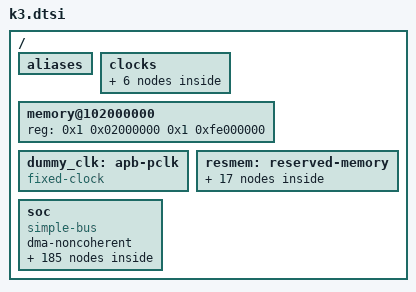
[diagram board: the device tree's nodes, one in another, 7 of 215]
// SPDX-License-Identifier: (GPL-2.0 OR MIT)
/* Copyright (c) 2025 Spacemit, Inc */

/dts-v1/;

/* Inline SoC GPIO helper: expand a linear GPIO to <bank,offset> */
#define K3_GPIO(x) ((x) / 32) ((x) % 32)
#include "k3-cpus.dtsi"
#include "k3-trace.dtsi"
#include <dt-bindings/gpio/gpio.h>
#include <dt-bindings/clock/spacemit,k3-syscon.h>
#include <dt-bindings/interrupt-controller/irq.h>
#include <dt-bindings/pmu/k3_pmu.h>
#include <dt-bindings/dma/k3-dmac.h>
#include <dt-bindings/leds/common.h>

/ {
	#address-cells = <2>;
	#size-cells = <2>;

	aliases {
		serial0 = &uart0;
		serial1 = &uart1;
		serial2 = &uart2;
		serial3 = &uart3;
		serial4 = &uart4;
		serial5 = &uart5;
		serial6 = &uart6;
		serial7 = &uart7;
		serial8 = &uart8;
		serial9 = &uart9;
		serial10 = &uart10;
		serial11 = &r_uart0;
		serial12 = &r_uart1;
		serial13 = &r_uart2;
		serial14 = &r_uart3;
		serial15 = &r_uart4;
		serial16 = &r_uart5;
		mmc0 = &sdcard;
		mmc1 = &sdio;
		mmc2 = &emmc;
		ethernet0 = &eth0;
		ethernet1 = &eth1;
		ethernet2 = &eth2;
		ethernet3 = &eth3;
		i2c0 = &i2c0;
		i2c1 = &i2c1;
		i2c2 = &i2c2;
		i2c3 = &i2c3;
		i2c4 = &i2c4;
		i2c5 = &i2c5;
		i2c6 = &i2c6;
		i2c8 = &i2c8;
		spi0 = &spi0;
		spi1 = &spi1;
		spi2 = &spi2;
		spi3 = &spi3;
	};

	clocks {
		vctcxo_1m: clock-1m {
			compatible = "fixed-clock";
			clock-frequency = <1000000>;
			clock-output-names = "vctcxo_1m";
			#clock-cells = <0>;
		};

		vctcxo_24m: clock-24m {
			compatible = "fixed-clock";
			clock-frequency = <24000000>;
			clock-output-names = "vctcxo_24m";
			#clock-cells = <0>;
		};

		vctcxo_3m: clock-3m {
			compatible = "fixed-clock";
			clock-frequency = <3000000>;
			clock-output-names = "vctcxo_3m";
			#clock-cells = <0>;
		};

		osc_32k: clock-32k {
			compatible = "fixed-clock";
			clock-frequency = <32768>;
			clock-output-names = "osc_32k";
			#clock-cells = <0>;
		};

		reserved_clk: clock-reserved {
			compatible = "fixed-clock";
			clock-frequency = <0>;
			clock-output-names = "reserved_clk";
			#clock-cells = <0>;
		};

		external_clk: clock-external {
			compatible = "fixed-clock";
			clock-frequency = <0>;
			clock-output-names = "external_clk";
			#clock-cells = <0>;
		};
	};

	memory@102000000 {
		device_type = "memory";
		reg = <0x1 0x02000000 0x1 0xfe000000>;
	};

	dummy_clk: apb-pclk {
		compatible = "fixed-clock";
		#clock-cells = <0x0>;
		clock-output-names = "clk14mhz";
		clock-frequency = <14000000>;
	};

	resmem: reserved-memory {
		#address-cells = <2>;
		#size-cells = <2>;
		ranges;

		/* used for rcpu0 code & data & bss space */
		rcpu0_pwr: rcpu0_pwr@100200000 {
			reg = <0x1 0x200000 0x0 0x300000>;
			no-map;
		};

		/* rcpu0's heap */
		rcpu0_heap: rcpu0_heap@100500000 {
			reg = <0x1 0x500000 0x0 0x200000>;
			no-map;
		};

		/* vring0 */
		rcpu0_vdev0vring0: vdev0vring0@c0876000 {
			reg = <0x0 0xc0876000 0x0 0x3000>;
			no-map;
		};

		/* vring1 */
		rcpu0_vdev0vring1: vdev0vring1@c0879000 {
			reg = <0x0 0xc0879000 0x0 0x3000>;
			no-map;
		};

		/* vring2 */
		rcpu0_vdev0vring2: vdev0vring2@c087c000 {
			reg = <0x0 0xc087c000 0x0 0x1000>;
			no-map;
		};

		/* the rcpu0's share memory buffer */
		rcpu0_vdev0buffer: vdev0buffer@100700000 {
			compatible = "shared-dma-pool";
			reg = <0x1 0x700000 0x0 0xfc000>;
			no-map;
		};

		/* the rcpu0's resource table */
		rcpu0_rsc_table: rcpu0_rsc_table@1007fc000 {
			reg = <0x1 0x7fc000 0x0 0x4000>;
			no-map;
		};

		/* rpmi */
		rpmi0: rpmi0@100800000 {
			reg = <0x1 0x00800000 0x0 0x4000>;
			no-map;
		};

		/*****************rcpu1**********************/
		/* used for rcp1 code & data & bss space */
		rcpu1_runtime: rcpu1_runtime@100804000 {
			reg = <0x1 0x804000 0x0 0x300000>;
			no-map;
		};

		/* rcpu1's heap */
		rcpu1_heap: rcpu1_heap@100B04000 {
			reg = <0x1 0xb04000 0x0 0x200000>;
			no-map;
		};

		/* vring0 */
		rcpu1_vdev0vring0: vdev0vring0@c086c000 {
			reg = <0x0 0xc086c000 0x0 0x3000>;
			no-map;
		};

		/* vring1 */
		rcpu1_vdev0vring1: vdev0vring1@c086f000 {
			reg = <0x0 0xc086f000 0x0 0x3000>;
			no-map;
		};

		/* the rcpu1's share memory buffer */
		rcpu1_vdev0buffer: vdev0buffer@100d04000 {
			compatible = "shared-dma-pool";
			reg = <0x1 0xd04000 0x0 0xfc000>;
			no-map;
		};

		/* the rcpu1's resource table */
		rcpu1_rsc_table: rcpu1_rsc_table@100e00000 {
			reg = <0x1 0xe00000 0x0 0x4000>;
			no-map;
		};

		/* reserve 3M for rcpu's dtb space */
		rcpu_dtb_table: rcpu_dtb_table@100e04000 {
			reg = <0x1 0xe04000 0x0 0x300000>;
			no-map;
		};

		/* reserved 5M for dpu, including mmu table and cmdlist */
		dpu_resv0: dpu_reserved@101b00000 {
			compatible = "shared-dma-pool";
			reg = <0x1 0x01b00000 0x0 0x00280000>;
			no-map;
		};

		dpu_resv1: dpu_reserved1@101d80000 {
			compatible = "shared-dma-pool";
			reg = <0x1 0x01d80000 0x0 0x00280000>;
			no-map;
		};
	};

	soc: soc {
		#address-cells = <2>;
		#size-cells = <2>;
		compatible = "simple-bus";
		dma-noncoherent;
		ranges;

		clint0: clint@e081c000 {
			compatible = "riscv,clint0";
			interrupts-extended = <
				&cpu0_intc  3 &cpu0_intc  7
				&cpu1_intc  3 &cpu1_intc  7
				&cpu2_intc  3 &cpu2_intc  7
				&cpu3_intc  3 &cpu3_intc  7
				&cpu4_intc  3 &cpu4_intc  7
				&cpu5_intc  3 &cpu5_intc  7
				&cpu6_intc  3 &cpu6_intc  7
				&cpu7_intc  3 &cpu7_intc  7
				&cpu8_intc  3 &cpu8_intc  7
				&cpu9_intc  3 &cpu9_intc  7
				&cpu10_intc  3 &cpu10_intc  7
				&cpu11_intc  3 &cpu11_intc  7
				&cpu12_intc  3 &cpu12_intc  7
				&cpu13_intc  3 &cpu13_intc  7
				&cpu14_intc  3 &cpu14_intc  7
				&cpu15_intc  3 &cpu15_intc  7
			>;
			reg = <0x0 0xe081c000 0x0 0x0004000>;
		};

		simsic: interrupt-controller@e0400000 {
			compatible = "riscv,imsics";
			interrupts-extended = <
				&cpu0_intc 9 &cpu1_intc 9
				&cpu2_intc 9 &cpu3_intc 9
				&cpu4_intc 9 &cpu5_intc 9
				&cpu6_intc 9 &cpu7_intc 9
				&cpu8_intc 9 &cpu9_intc 9
				&cpu10_intc 9 &cpu11_intc 9
				&cpu12_intc 9 &cpu13_intc 9
				&cpu14_intc 9 &cpu15_intc 9>;

			reg = <0x0 0xe0400000 0x0 0x400000>;
			interrupt-controller;
			#interrupt-cells = <0>;
			#msi-cells = <0>;
			msi-controller;
			/* Number of interrupt identities: 511 */
			riscv,num-ids = <511>;
			/* Number of guest interrupt identities: 511 */
			riscv,num-guest-ids = <511>;
			/* Number of HART index bits: 4 (2^4 = 16 harts) */
			riscv,hart-index-bits = <4>;
			/*
			 * Number of guest index bits: 6
			 *    2^6 = 64 interrupt files
			 *        = 1 s-level interrupt file + 63 vs-level interrupt files
			 *
			 * But on K3,
			 *   X100: only 7 of the 63 vs-level interrupt files are valid.
			 *   A100: no valid vs-level interrupt files.
			 */
			riscv,guest-index-bits = <6>;
			status = "okay";
		};

		saplic: interrupt-controller@e0804000 {
			compatible = "riscv,aplic";
			/* aplic config */
			reg = <0x0 0xe0804000 0x0 0x4000>;
			msi-parent = <&simsic>;
			#interrupt-cells = <2>;
			interrupt-controller;
			/* the number of wired interrupt sources:512 */
			riscv,num-sources = <512>;
			status = "okay";
		};

		syscon_mpmu: system-controller@d4050000 {
			compatible = "spacemit,k3-syscon-mpmu";
			reg = <0x0 0xd4050000 0x0 0x10000>;
			clocks = <&osc_32k>, <&vctcxo_1m>, <&vctcxo_3m>,
				 <&vctcxo_24m>, <&reserved_clk>, <&external_clk>;
			clock-names = "osc_32k", "vctcxo_1m", "vctcxo_3m", "vctcxo_24m",
				      "reserved_clk", "external_clk";
			#clock-cells = <1>;
			#reset-cells = <1>;
		};

		pll: clock-controller@d4090000 {
			compatible = "spacemit,k3-pll";
			reg = <0x0 0xd4090000 0x0 0x10000>;
			clocks = <&vctcxo_24m>;
			spacemit,mpmu = <&syscon_mpmu>;
			#clock-cells = <1>;
		};

		syscon_apmu: system-controller@d4282800 {
			compatible = "spacemit,k3-syscon-apmu";
			reg = <0x0 0xd4282800 0x0 0x400>;
			clocks = <&osc_32k>, <&vctcxo_1m>, <&vctcxo_3m>, <&vctcxo_24m>,
				 <&reserved_clk>, <&external_clk>;
			clock-names = "osc_32k", "vctcxo_1m", "vctcxo_3m", "vctcxo_24m",
				      "reserved_clk", "external_clk";
			#clock-cells = <1>;
			#power-domain-cells = <1>;
			#reset-cells = <1>;
		};

		syscon_apbc: system-controller@d4015000 {
			compatible = "spacemit,k3-syscon-apbc";
			reg = <0x0 0xd4015000 0x0 0x1000>;
			clocks = <&osc_32k>, <&vctcxo_1m>, <&vctcxo_3m>, <&vctcxo_24m>,
				 <&reserved_clk>, <&external_clk>;
			clock-names = "osc_32k", "vctcxo_1m", "vctcxo_3m", "vctcxo_24m",
				      "reserved_clk", "external_clk";
			#clock-cells = <1>;
			#reset-cells = <1>;
		};

		syscon_apbc2: system-controller@f0610000 {
			compatible = "spacemit,k3-syscon-apbc2";
			reg = <0x0 0xf0610000 0x0 0x2000>;
			clocks = <&osc_32k>, <&vctcxo_1m>, <&vctcxo_3m>, <&vctcxo_24m>,
				 <&reserved_clk>, <&external_clk>;
			clock-names = "osc_32k", "vctcxo_1m", "vctcxo_3m", "vctcxo_24m",
				      "reserved_clk", "external_clk";
			#clock-cells = <1>;
			#reset-cells = <1>;
		};

		syscon_dciu: system-controller@d8440000 {
			compatible = "spacemit,k3-syscon-dciu";
			reg = <0x0 0xd8440000 0x0 0xc000>;
			#clock-cells = <1>;
			#reset-cells = <1>;
		};

		syscon_rcpu_sysctrl: system-controller@c0880000 {
			compatible = "spacemit,k3-syscon-rcpu-sysctrl";
			reg = <0x0 0xc0880000 0x0 0x1000>;
			clocks = <&vctcxo_24m>, <&external_clk>;
			clock-names = "vctcxo_24m", "external_clk";
			#clock-cells = <1>;
			#reset-cells = <1>;
		};

		syscon_rcpu_uartctrl: system-controller@c0881f00 {
			compatible = "spacemit,k3-syscon-rcpu-uartctrl";
			reg = <0x0 0xc0881f00 0x0 0x100>;
			#clock-cells = <1>;
			#reset-cells = <1>;
		};

		syscon_rcpu_i2sctrl: system-controller@c0882000 {
			compatible = "spacemit,k3-syscon-rcpu-i2sctrl";
			reg = <0x0 0xc0882000 0x0 0x1000>;
			#clock-cells = <1>;
			#reset-cells = <1>;
		};

		syscon_rcpu_spictrl: system-controller@c0885f00 {
			compatible = "spacemit,k3-syscon-rcpu-spictrl";
			reg = <0x0 0xc0885f00 0x0 0x100>;
			#clock-cells = <1>;
			#reset-cells = <1>;
		};

		syscon_rcpu_i2cctrl: system-controller@c0886f00 {
			compatible = "spacemit,k3-syscon-rcpu-i2cctrl";
			reg = <0x0 0xc0886f00 0x0 0x100>;
			#clock-cells = <1>;
			#reset-cells = <1>;
		};

		syscon_rpmu: system-controller@c088c000 {
			compatible = "spacemit,k3-syscon-rpmu";
			reg = <0x0 0xc088c000 0x0 0x800>;
			#clock-cells = <1>;
			#reset-cells = <1>;
		};

		syscon_rcpu_pwmctrl: system-controller@c088d000 {
			compatible = "spacemit,k3-syscon-rcpu-pwmctrl";
			reg = <0x0 0xc088d000 0x0 0x100>;
			#clock-cells = <1>;
			#reset-cells = <1>;
		};

		syscon_gpio: syscon-gpio{
			compatible = "syscon";
			reg = <0x0 0xd4019000 0x0 0x800>;
		};

		syscon_gpio_edge: syscon-gpio-edge{
			compatible = "syscon";
			reg = <0x0 0xd4019800 0x0 0x10>;
		};

		gpio: gpio@d4019000 {
			compatible = "spacemit,k3-gpio";
			reg = <0x0 0xd4019000 0x0 0x100>;
			clocks = <&syscon_apbc CLK_APBC_GPIO>,
				 <&syscon_apbc CLK_APBC_GPIO_BUS>;
			clock-names = "core", "bus";
			gpio-controller;
			#gpio-cells = <3>;
			interrupts = <58 IRQ_TYPE_LEVEL_HIGH>;
			interrupt-parent = <&saplic>;
			interrupt-controller;
			#interrupt-cells = <3>;
			syscon-gpio-regs = <&syscon_gpio>;
			syscon-gpio-edge = <&syscon_gpio_edge>;
			gpio-ranges = <&pinctrl 0 0 0 32>,
				      <&pinctrl 1 0 32 32>,
				      <&pinctrl 2 0 64 32>,
				      <&pinctrl 3 0 96 32>;
		};

		pinctrl: pinctrl@d401e000 {
			compatible = "spacemit,k3-pinctrl";
			reg = <0x0 0xd401e000 0x0 0x400>,
			      <0x0 0xd401e800 0x0 0x34>;
			clocks = <&syscon_apbc CLK_APBC_AIB>,
                                <&syscon_apbc CLK_APBC_AIB_BUS>;
			clock-names = "func", "bus";
			interrupt-controller;
			#interrupt-cells = <2>;
			interrupts = <60 IRQ_TYPE_LEVEL_HIGH>;
			interrupt-parent = <&saplic>;
			spacemit,gpio-edge = <&syscon_gpio_edge>;
			spacemit,apbc = <&syscon_apbc 0x50>;
			spacemit,apmu = <&syscon_apmu>;
		};

		pdma: pdma@d4000000 {
			compatible = "spacemit,k1-pdma";
			reg = <0x0 0xd4000000 0x0 0x4000>;
			interrupt-parent = <&saplic>;
			interrupts = <72 IRQ_TYPE_LEVEL_HIGH>;
			clocks = <&syscon_apmu CLK_APMU_DMA>;
			resets = <&syscon_apmu RESET_APMU_DMA>;
			#dma-cells= <1>;
			#dma-channels = <16>;
			max-burst-size = <64>;
			status = "okay";
		};

		pdma1: pdma@f0600000 {
			compatible = "spacemit,k1-pdma";
			reg = <0x0 0xf0600000 0x0 0x4000>;
			interrupt-parent = <&saplic>;
			interrupts = <150 IRQ_TYPE_LEVEL_HIGH>;
			#dma-cells= <1>;
			#dma-channels = <16>;
			max-burst-size = <64>;
			status = "disabled";
		};

		udma: udma {
			compatible = "spacemit,udma";
			status = "okay";
		};

		uart0: serial@d4017000 {
			compatible = "spacemit,k1-uart",
				     "intel,xscale-uart";
			reg = <0x0 0xd4017000 0x0 0x100>;
			clocks = <&syscon_apbc CLK_APBC_UART0>,
				 <&syscon_apbc CLK_APBC_UART0_BUS>,
				 <&syscon_mpmu CLK_MPMU_SLOW_UART>;
			clock-names = "core", "bus", "gate";
			resets = <&syscon_apbc RESET_APBC_UART0>;
			reg-shift = <2>;
			reg-io-width = <4>;
			fifo-size = <256>;
			tx-threshold = <32>;
			interrupt-parent = <&saplic>;
			interrupts = <42 IRQ_TYPE_LEVEL_HIGH>;
			status = "okay";
		};

		uart1: serial@f0612000 {
			compatible = "spacemit,k1-uart",
				     "intel,xscale-uart";
			reg = <0x0 0xf0612000 0x0 0x100>;
			clocks = <&syscon_apbc2 CLK_APBC2_SEC_UART1>,
				 <&syscon_apbc2 CLK_APBC2_SEC_UART1_BUS>,
				 <&syscon_mpmu CLK_MPMU_SLOW_UART>;
			clock-names = "core", "bus", "gate";
			resets = <&syscon_apbc2 RESET_APBC2_SEC_UART1>;
			reg-shift = <2>;
			reg-io-width = <4>;
			fifo-size = <256>;
			tx-threshold = <32>;
			interrupt-parent = <&saplic>;
			interrupts = <43 IRQ_TYPE_LEVEL_HIGH>;
			status = "disabled";
		};

		uart2: serial@d4017100 {
			compatible = "spacemit,k1-uart",
				     "intel,xscale-uart";
			reg = <0x0 0xd4017100 0x0 0x100>;
			clocks = <&syscon_apbc CLK_APBC_UART2>,
				 <&syscon_apbc CLK_APBC_UART2_BUS>,
				 <&syscon_mpmu CLK_MPMU_SLOW_UART>;
			clock-names = "core", "bus", "gate";
			resets = <&syscon_apbc RESET_APBC_UART2>;
			reg-shift = <2>;
			reg-io-width = <4>;
			fifo-size = <256>;
			tx-threshold = <32>;
			interrupt-parent = <&saplic>;
			interrupts = <44 IRQ_TYPE_LEVEL_HIGH>;
			status = "disabled";
		};

		uart3: serial@d4017200 {
			compatible = "spacemit,k1-uart",
				     "intel,xscale-uart";
			reg = <0x0 0xd4017200 0x0 0x100>;
			clocks = <&syscon_apbc CLK_APBC_UART3>,
				 <&syscon_apbc CLK_APBC_UART3_BUS>,
				 <&syscon_mpmu CLK_MPMU_SLOW_UART>;
			clock-names = "core", "bus", "gate";
			resets = <&syscon_apbc RESET_APBC_UART3>;
			reg-shift = <2>;
			reg-io-width = <4>;
			fifo-size = <256>;
			tx-threshold = <32>;
			interrupt-parent = <&saplic>;
			interrupts = <45 IRQ_TYPE_LEVEL_HIGH>;
			status = "disabled";
		};

		uart4: serial@d4017300 {
			compatible = "spacemit,k1-uart",
				     "intel,xscale-uart";
			reg = <0x0 0xd4017300 0x0 0x100>;
			clocks = <&syscon_apbc CLK_APBC_UART4>,
				 <&syscon_apbc CLK_APBC_UART4_BUS>,
				 <&syscon_mpmu CLK_MPMU_SLOW_UART>;
			clock-names = "core", "bus", "gate";
			resets = <&syscon_apbc RESET_APBC_UART4>;
			reg-shift = <2>;
			reg-io-width = <4>;
			fifo-size = <256>;
			tx-threshold = <32>;
			interrupt-parent = <&saplic>;
			interrupts = <46 IRQ_TYPE_LEVEL_HIGH>;
			status = "disabled";
		};

		uart5: serial@d4017400 {
			compatible = "spacemit,k1-uart",
				     "intel,xscale-uart";
			reg = <0x0 0xd4017400 0x0 0x100>;
			clocks = <&syscon_apbc CLK_APBC_UART5>,
				 <&syscon_apbc CLK_APBC_UART5_BUS>,
				 <&syscon_mpmu CLK_MPMU_SLOW_UART>;
			clock-names = "core", "bus", "gate";
			resets = <&syscon_apbc RESET_APBC_UART5>;
			reg-shift = <2>;
			reg-io-width = <4>;
			fifo-size = <256>;
			tx-threshold = <32>;
			interrupt-parent = <&saplic>;
			interrupts = <47 IRQ_TYPE_LEVEL_HIGH>;
			status = "disabled";
		};

		uart6: serial@d4017500 {
			compatible = "spacemit,k1-uart",
				     "intel,xscale-uart";
			reg = <0x0 0xd4017500 0x0 0x100>;
			clocks = <&syscon_apbc CLK_APBC_UART6>,
				 <&syscon_apbc CLK_APBC_UART6_BUS>,
				 <&syscon_mpmu CLK_MPMU_SLOW_UART>;
			clock-names = "core", "bus", "gate";
			resets = <&syscon_apbc RESET_APBC_UART6>;
			reg-shift = <2>;
			reg-io-width = <4>;
			fifo-size = <256>;
			tx-threshold = <32>;
			interrupt-parent = <&saplic>;
			interrupts = <48 IRQ_TYPE_LEVEL_HIGH>;
			status = "disabled";
		};

		uart7: serial@d4017600 {
			compatible = "spacemit,k1-uart",
				     "intel,xscale-uart";
			reg = <0x0 0xd4017600 0x0 0x100>;
			clocks = <&syscon_apbc CLK_APBC_UART7>,
				 <&syscon_apbc CLK_APBC_UART7_BUS>,
				 <&syscon_mpmu CLK_MPMU_SLOW_UART>;
			clock-names = "core", "bus", "gate";
			resets = <&syscon_apbc RESET_APBC_UART7>;
			reg-shift = <2>;
			reg-io-width = <4>;
			fifo-size = <256>;
			tx-threshold = <32>;
			interrupt-parent = <&saplic>;
			interrupts = <49 IRQ_TYPE_LEVEL_HIGH>;
			status = "disabled";
		};

		uart8: serial@d4017700 {
			compatible = "spacemit,k1-uart",
				     "intel,xscale-uart";
			reg = <0x0 0xd4017700 0x0 0x100>;
			clocks = <&syscon_apbc CLK_APBC_UART8>,
				 <&syscon_apbc CLK_APBC_UART8_BUS>,
				 <&syscon_mpmu CLK_MPMU_SLOW_UART>;
			clock-names = "core", "bus", "gate";
			resets = <&syscon_apbc RESET_APBC_UART8>;
			reg-shift = <2>;
			reg-io-width = <4>;
			fifo-size = <256>;
			tx-threshold = <32>;
			interrupt-parent = <&saplic>;
			interrupts = <50 IRQ_TYPE_LEVEL_HIGH>;
			status = "disabled";
		};

		uart9: serial@d4017800 {
			compatible = "spacemit,k1-uart",
				     "intel,xscale-uart";
			reg = <0x0 0xd4017800 0x0 0x100>;
			clocks = <&syscon_apbc CLK_APBC_UART9>,
				 <&syscon_apbc CLK_APBC_UART9_BUS>,
				 <&syscon_mpmu CLK_MPMU_SLOW_UART>;
			clock-names = "core", "bus", "gate";
			resets = <&syscon_apbc RESET_APBC_UART9>;
			reg-shift = <2>;
			reg-io-width = <4>;
			fifo-size = <256>;
			tx-threshold = <32>;
			interrupt-parent = <&saplic>;
			interrupts = <51 IRQ_TYPE_LEVEL_HIGH>;
			status = "disabled";
		};

		uart10: serial@d401f000 {
			compatible = "spacemit,k1-uart",
				     "intel,xscale-uart";
			reg = <0x0 0xd401f000 0x0 0x100>;
			clocks = <&syscon_apbc CLK_APBC_UART10>,
				 <&syscon_apbc CLK_APBC_UART10_BUS>,
				 <&syscon_mpmu CLK_MPMU_SLOW_UART>;
			clock-names = "core", "bus", "gate";
			resets = <&syscon_apbc RESET_APBC_UART10>;
			reg-shift = <2>;
			reg-io-width = <4>;
			fifo-size = <256>;
			tx-threshold = <32>;
			interrupt-parent = <&saplic>;
			interrupts = <281 IRQ_TYPE_LEVEL_HIGH>;
			status = "disabled";
		};

		i2c0: i2c@d4010800 {
			compatible = "spacemit,k1-i2c";
			reg = <0x0 0xd4010800 0x0 0x38>;
			#address-cells = <1>;
			#size-cells = <0>;
			interrupt-parent = <&saplic>;
			interrupts = <36 IRQ_TYPE_LEVEL_HIGH>;
			clocks = <&syscon_apbc CLK_APBC_TWSI0>,
				 <&syscon_apbc CLK_APBC_TWSI0_BUS>;
			clock-names = "func", "bus";
			clock-frequency = <400000>;
			resets = <&syscon_apbc RESET_APBC_TWSI0>;
			power-domains = <&power K3_PMU_DUMMY_PWR_DOMAIN>;
			status = "disabled";
		};

		i2c1: i2c@d4011000 {
			compatible = "spacemit,k1-i2c";
			reg = <0x0 0xd4011000 0x0 0x38>;
			#address-cells = <1>;
			#size-cells = <0>;
			interrupt-parent = <&saplic>;
			interrupts = <37 IRQ_TYPE_LEVEL_HIGH>;
			clocks = <&syscon_apbc CLK_APBC_TWSI1>,
				 <&syscon_apbc CLK_APBC_TWSI1_BUS>;
			clock-names = "func", "bus";
			clock-frequency = <400000>;
			resets = <&syscon_apbc RESET_APBC_TWSI1>;
			power-domains = <&power K3_PMU_DUMMY_PWR_DOMAIN>;
			status = "disabled";
		};

		i2c2: i2c@d4012000 {
			compatible = "spacemit,k1-i2c";
			reg = <0x0 0xd4012000 0x0 0x38>;
			#address-cells = <1>;
			#size-cells = <0>;
			interrupt-parent = <&saplic>;
			interrupts = <38 IRQ_TYPE_LEVEL_HIGH>;
			clocks = <&syscon_apbc CLK_APBC_TWSI2>,
				 <&syscon_apbc CLK_APBC_TWSI2_BUS>;
			clock-names = "func", "bus";
			clock-frequency = <400000>;
			resets = <&syscon_apbc RESET_APBC_TWSI2>;
			power-domains = <&power K3_PMU_DUMMY_PWR_DOMAIN>;
			status = "disabled";
		};

		i2c3: i2c@f0614000 {
			compatible = "spacemit,k1-i2c";
			reg = <0x0 0xf0614000 0x0 0x38>;
			#address-cells = <1>;
			#size-cells = <0>;
			interrupt-parent = <&saplic>;
			interrupts = <39 IRQ_TYPE_LEVEL_HIGH>;
			clocks = <&syscon_apbc2 CLK_APBC2_SEC_TWSI3>,
				 <&syscon_apbc2 CLK_APBC2_SEC_TWSI3_BUS>;
			clock-names = "func", "bus";
			clock-frequency = <400000>;
			resets = <&syscon_apbc2 RESET_APBC2_SEC_TWSI3>;
			power-domains = <&power K3_PMU_DUMMY_PWR_DOMAIN>;
			status = "disabled";
		};

		i2c4: i2c@d4012800 {
			compatible = "spacemit,k1-i2c";
			reg = <0x0 0xd4012800 0x0 0x38>;
			#address-cells = <1>;
			#size-cells = <0>;
			interrupt-parent = <&saplic>;
			interrupts = <40 IRQ_TYPE_LEVEL_HIGH>;
			clocks = <&syscon_apbc CLK_APBC_TWSI4>,
				 <&syscon_apbc CLK_APBC_TWSI4_BUS>;
			clock-names = "func", "bus";
			clock-frequency = <400000>;
			resets = <&syscon_apbc RESET_APBC_TWSI4>;
			power-domains = <&power K3_PMU_DUMMY_PWR_DOMAIN>;
			status = "disabled";
		};

		i2c5: i2c@d4013800 {
			compatible = "spacemit,k1-i2c";
			reg = <0x0 0xd4013800 0x0 0x38>;
			#address-cells = <1>;
			#size-cells = <0>;
			interrupt-parent = <&saplic>;
			interrupts = <41 IRQ_TYPE_LEVEL_HIGH>;
			clocks = <&syscon_apbc CLK_APBC_TWSI5>,
				 <&syscon_apbc CLK_APBC_TWSI5_BUS>;
			clock-names = "func", "bus";
			clock-frequency = <400000>;
			resets = <&syscon_apbc RESET_APBC_TWSI5>;
			power-domains = <&power K3_PMU_DUMMY_PWR_DOMAIN>;
			status = "disabled";
		};

		i2c6: i2c@d4018800 {
			compatible = "spacemit,k1-i2c";
			reg = <0x0 0xd4018800 0x0 0x38>;
			#address-cells = <1>;
			#size-cells = <0>;
			interrupt-parent = <&saplic>;
			interrupts = <70 IRQ_TYPE_LEVEL_HIGH>;
			clocks = <&syscon_apbc CLK_APBC_TWSI6>,
				 <&syscon_apbc CLK_APBC_TWSI6_BUS>;
			clock-names = "func", "bus";
			clock-frequency = <400000>;
			resets = <&syscon_apbc RESET_APBC_TWSI6>;
			power-domains = <&power K3_PMU_DUMMY_PWR_DOMAIN>;
			status = "disabled";
		};

		i2c8: i2c@d401d800 {
			compatible = "spacemit,k1-i2c";
			reg = <0x0 0xd401d800 0x0 0x38>;
			#address-cells = <1>;
			#size-cells = <0>;
			interrupt-parent = <&saplic>;
			interrupts = <19 IRQ_TYPE_LEVEL_HIGH>;
			clocks = <&syscon_apbc CLK_APBC_TWSI8>,
				 <&syscon_apbc CLK_APBC_TWSI8_BUS>;
			clock-names = "func", "bus";
			clock-frequency = <400000>;
			resets = <&syscon_apbc RESET_APBC_TWSI8>;
			power-domains = <&power K3_PMU_DUMMY_PWR_DOMAIN>;
			status = "disabled";
		};

		pwm0: pwm@d401a000 {
			compatible = "spacemit,k1-pwm", "marvell,pxa910-pwm";
			reg = <0x0 0xd401a000 0x0 0x10>;
			clocks = <&syscon_apbc CLK_APBC_PWM0>,<&syscon_apbc CLK_APBC_PWM0_BUS>;
			clock-names = "func", "bus";
			resets = <&syscon_apbc RESET_APBC_PWM0>;
			#pwm-cells = <3>;
			k1,pwm-disable-fd;
			status = "disabled";
		};

		pwm1: pwm@d401a400 {
			compatible = "spacemit,k1-pwm", "marvell,pxa910-pwm";
			reg = <0x0 0xd401a400 0x0 0x10>;
			clocks = <&syscon_apbc CLK_APBC_PWM1>,<&syscon_apbc CLK_APBC_PWM1_BUS>;
			clock-names = "func", "bus";
			resets = <&syscon_apbc RESET_APBC_PWM1>;
			#pwm-cells = <3>;
			k1,pwm-disable-fd;
			status = "disabled";
		};

		pwm2: pwm@d401a800 {
			compatible = "spacemit,k1-pwm", "marvell,pxa910-pwm";
			reg = <0x0 0xd401a800 0x0 0x10>;
			clocks = <&syscon_apbc CLK_APBC_PWM2>,<&syscon_apbc CLK_APBC_PWM2_BUS>;
			clock-names = "func", "bus";
			resets = <&syscon_apbc RESET_APBC_PWM2>;
			#pwm-cells = <3>;
			k1,pwm-disable-fd;
			status = "disabled";
		};

		pwm3: pwm@d401ac00 {
			compatible = "spacemit,k1-pwm", "marvell,pxa910-pwm";
			reg = <0x0 0xd401ac00 0x0 0x10>;
			clocks = <&syscon_apbc CLK_APBC_PWM3>,<&syscon_apbc CLK_APBC_PWM3_BUS>;
			clock-names = "func", "bus";
			resets = <&syscon_apbc RESET_APBC_PWM3>;
			#pwm-cells = <3>;
			k1,pwm-disable-fd;
			status = "disabled";
		};

		pwm4: pwm@d401b000 {
			compatible = "spacemit,k1-pwm", "marvell,pxa910-pwm";
			reg = <0x0 0xd401b000 0x0 0x10>;
			clocks = <&syscon_apbc CLK_APBC_PWM4>,<&syscon_apbc CLK_APBC_PWM4_BUS>;
			clock-names = "func", "bus";
			resets = <&syscon_apbc RESET_APBC_PWM4>;
			#pwm-cells = <3>;
			k1,pwm-disable-fd;
			status = "disabled";
		};

		pwm5: pwm@d401b400 {
			compatible = "spacemit,k1-pwm", "marvell,pxa910-pwm";
			reg = <0x0 0xd401b400 0x0 0x10>;
			clocks = <&syscon_apbc CLK_APBC_PWM5>,<&syscon_apbc CLK_APBC_PWM5_BUS>;
			clock-names = "func", "bus";
			resets = <&syscon_apbc RESET_APBC_PWM5>;
			#pwm-cells = <3>;
			k1,pwm-disable-fd;
			status = "disabled";
		};

		pwm6: pwm@d401b800 {
			compatible = "spacemit,k1-pwm", "marvell,pxa910-pwm";
			reg = <0x0 0xd401b800 0x0 0x10>;
			clocks = <&syscon_apbc CLK_APBC_PWM6>,<&syscon_apbc CLK_APBC_PWM6_BUS>;
			clock-names = "func", "bus";
			resets = <&syscon_apbc RESET_APBC_PWM6>;
			#pwm-cells = <3>;
			k1,pwm-disable-fd;
			status = "disabled";
		};

		pwm7: pwm@d401bc00 {
			compatible = "spacemit,k1-pwm", "marvell,pxa910-pwm";
			reg = <0x0 0xd401bc00 0x0 0x10>;
			clocks = <&syscon_apbc CLK_APBC_PWM7>,<&syscon_apbc CLK_APBC_PWM7_BUS>;
			clock-names = "func", "bus";
			resets = <&syscon_apbc RESET_APBC_PWM7>;
			#pwm-cells = <3>;
			k1,pwm-disable-fd;
			status = "disabled";
		};

		pwm8: pwm@d4020000 {
			compatible = "spacemit,k1-pwm", "marvell,pxa910-pwm";
			reg = <0x0 0xd4020000 0x0 0x10>;
			clocks = <&syscon_apbc CLK_APBC_PWM8>,<&syscon_apbc CLK_APBC_PWM8_BUS>;
			clock-names = "func", "bus";
			resets = <&syscon_apbc RESET_APBC_PWM8>;
			#pwm-cells = <3>;
			k1,pwm-disable-fd;
			status = "disabled";
		};

		pwm9: pwm@d4020400 {
			compatible = "spacemit,k1-pwm", "marvell,pxa910-pwm";
			reg = <0x0 0xd4020400 0x0 0x10>;
			clocks = <&syscon_apbc CLK_APBC_PWM9>,<&syscon_apbc CLK_APBC_PWM9_BUS>;
			clock-names = "func", "bus";
			resets = <&syscon_apbc RESET_APBC_PWM9>;
			#pwm-cells = <3>;
			k1,pwm-disable-fd;
			status = "disabled";
		};

		pwm10: pwm@d4020800 {
			compatible = "spacemit,k1-pwm", "marvell,pxa910-pwm";
			reg = <0x0 0xd4020800 0x0 0x10>;
			clocks = <&syscon_apbc CLK_APBC_PWM10>,<&syscon_apbc CLK_APBC_PWM10_BUS>;
			clock-names = "func", "bus";
			resets = <&syscon_apbc RESET_APBC_PWM10>;
			#pwm-cells = <3>;
			k1,pwm-disable-fd;
			status = "disabled";
		};

		pwm11: pwm@d4020c00 {
			compatible = "spacemit,k1-pwm", "marvell,pxa910-pwm";
			reg = <0x0 0xd4020c00 0x0 0x10>;
			clocks = <&syscon_apbc CLK_APBC_PWM11>,<&syscon_apbc CLK_APBC_PWM11_BUS>;
			clock-names = "func", "bus";
			resets = <&syscon_apbc RESET_APBC_PWM11>;
			#pwm-cells = <3>;
			k1,pwm-disable-fd;
			status = "disabled";
		};

		pwm12: pwm@d4021000 {
			compatible = "spacemit,k1-pwm", "marvell,pxa910-pwm";
			reg = <0x0 0xd4021000 0x0 0x10>;
			clocks = <&syscon_apbc CLK_APBC_PWM12>,<&syscon_apbc CLK_APBC_PWM12_BUS>;
			clock-names = "func", "bus";
			resets = <&syscon_apbc RESET_APBC_PWM12>;
			#pwm-cells = <3>;
			k1,pwm-disable-fd;
			status = "disabled";
		};

		pwm13: pwm@d4021400 {
			compatible = "spacemit,k1-pwm", "marvell,pxa910-pwm";
			reg = <0x0 0xd4021400 0x0 0x10>;
			clocks = <&syscon_apbc CLK_APBC_PWM13>,<&syscon_apbc CLK_APBC_PWM13_BUS>;
			clock-names = "func", "bus";
			resets = <&syscon_apbc RESET_APBC_PWM13>;
			#pwm-cells = <3>;
			k1,pwm-disable-fd;
			status = "disabled";
		};

		pwm14: pwm@d4021800 {
			compatible = "spacemit,k1-pwm", "marvell,pxa910-pwm";
			reg = <0x0 0xd4021800 0x0 0x10>;
			clocks = <&syscon_apbc CLK_APBC_PWM14>,<&syscon_apbc CLK_APBC_PWM14_BUS>;
			clock-names = "func", "bus";
			resets = <&syscon_apbc RESET_APBC_PWM14>;
			#pwm-cells = <3>;
			k1,pwm-disable-fd;
			status = "disabled";
		};

		pwm15: pwm@d4021c00 {
			compatible = "spacemit,k1-pwm", "marvell,pxa910-pwm";
			reg = <0x0 0xd4021c00 0x0 0x10>;
			clocks = <&syscon_apbc CLK_APBC_PWM15>,<&syscon_apbc CLK_APBC_PWM15_BUS>;
			clock-names = "func", "bus";
			resets = <&syscon_apbc RESET_APBC_PWM15>;
			#pwm-cells = <3>;
			k1,pwm-disable-fd;
			status = "disabled";
		};

		pwm16: pwm@d4022000 {
			compatible = "spacemit,k1-pwm", "marvell,pxa910-pwm";
			reg = <0x0 0xd4022000 0x0 0x10>;
			clocks = <&syscon_apbc CLK_APBC_PWM16>,<&syscon_apbc CLK_APBC_PWM16_BUS>;
			clock-names = "func", "bus";
			resets = <&syscon_apbc RESET_APBC_PWM16>;
			#pwm-cells = <3>;
			k1,pwm-disable-fd;
			status = "disabled";
		};

		pwm17: pwm@d4022400 {
			compatible = "spacemit,k1-pwm", "marvell,pxa910-pwm";
			reg = <0x0 0xd4022400 0x0 0x10>;
			clocks = <&syscon_apbc CLK_APBC_PWM17>,<&syscon_apbc CLK_APBC_PWM17_BUS>;
			clock-names = "func", "bus";
			resets = <&syscon_apbc RESET_APBC_PWM17>;
			#pwm-cells = <3>;
			k1,pwm-disable-fd;
			status = "disabled";
		};

		pwm18: pwm@d4022800 {
			compatible = "spacemit,k1-pwm", "marvell,pxa910-pwm";
			reg = <0x0 0xd4022800 0x0 0x10>;
			clocks = <&syscon_apbc CLK_APBC_PWM18>,<&syscon_apbc CLK_APBC_PWM18_BUS>;
			clock-names = "func", "bus";
			resets = <&syscon_apbc RESET_APBC_PWM18>;
			#pwm-cells = <3>;
			k1,pwm-disable-fd;
			status = "disabled";
		};

		pwm19: pwm@d4022c00 {
			compatible = "spacemit,k1-pwm", "marvell,pxa910-pwm";
			reg = <0x0 0xd4022c00 0x0 0x10>;
			clocks = <&syscon_apbc CLK_APBC_PWM19>,<&syscon_apbc CLK_APBC_PWM19_BUS>;
			clock-names = "func", "bus";
			resets = <&syscon_apbc RESET_APBC_PWM19>;
			#pwm-cells = <3>;
			k1,pwm-disable-fd;
			status = "disabled";
		};

		spi0: spi@d4040000 {
			compatible = "spacemit,k3-spi";
			reg = <0x0 0xd4040000 0x0 0x30>;
			dmas = <&pdma DMA_SSP0_TX
				&pdma DMA_SSP0_RX>;
			dma-names = "tx", "rx";
			interrupt-parent = <&saplic>;
			interrupts = <283 IRQ_TYPE_LEVEL_HIGH>;
			clocks = <&syscon_apbc  CLK_APBC_SPI0>,
				<&syscon_apbc CLK_APBC_SPI0_BUS>;
			clock-names = "func", "bus";
			resets = <&syscon_apbc RESET_APBC_SPI0>;
			spi-max-frequency = <51200000>;
			#address-cells = <1>;
			#size-cells = <0>;
			status = "disabled";
		};

		spi1: spi@d4040800 {
			compatible = "spacemit,k3-spi";
			reg = <0x0 0xd4040800 0x0 0x30>;
			dmas = <&pdma DMA_SSP1_TX
				&pdma DMA_SSP1_RX>;
			dma-names = "tx", "rx";
			interrupt-parent = <&saplic>;
			interrupts = <282 IRQ_TYPE_LEVEL_HIGH>;
			clocks = <&syscon_apbc  CLK_APBC_SPI1>,
				<&syscon_apbc CLK_APBC_SPI1_BUS>;
			clock-names = "func", "bus";
			resets = <&syscon_apbc RESET_APBC_SPI1>;
			spi-max-frequency = <51200000>;
			#address-cells = <1>;
			#size-cells = <0>;
			status = "disabled";
		};

		spi2: spi@f0613000 {
			compatible = "spacemit,k3-spi";
			reg = <0x0 0xf0613000 0x0 0x30>;
			// dmas = <&pdma 19
			// 	&pdma 20>;
			// dma-names = "rx", "tx";
			interrupt-parent = <&saplic>;
			interrupts = <54 IRQ_TYPE_LEVEL_HIGH>;
			clocks = <&syscon_apbc2 CLK_APBC2_SEC_SPI2>,
				 <&syscon_apbc2 CLK_APBC2_SEC_SPI2_BUS>;
			clock-names = "func", "bus";
			resets = <&syscon_apbc2 RESET_APBC2_SEC_SPI2>;
			spi-max-frequency = <51200000>;
			#address-cells = <1>;
			#size-cells = <0>;
			status = "disabled";
		};

		spi3: spi@d401c000 {
			compatible = "spacemit,k3-spi";
			reg = <0x0 0xd401c000 0x0 0x30>;
			dmas = <&pdma DMA_SSP3_TX
				&pdma DMA_SSP3_RX>;
			dma-names = "tx", "rx";
			interrupt-parent = <&saplic>;
			interrupts = <55 IRQ_TYPE_LEVEL_HIGH>;
			clocks = <&syscon_apbc CLK_APBC_SPI3>,
				<&syscon_apbc CLK_APBC_SPI3_BUS>;
			clock-names = "func", "bus";
			resets = <&syscon_apbc RESET_APBC_SPI3>;
			spi-max-frequency = <51200000>;
			#address-cells = <1>;
			#size-cells = <0>;
			status = "disabled";
		};

		qspi: spi@d420c000 {
			compatible = "spacemit,k3-qspi";
			#address-cells = <1>;
			#size-cells = <0>;
			reg = <0x0 0xd420c000 0x0 0x1000>,
			      <0x0 0xb8000000 0x0 0xc00000>;
			reg-names = "QuadSPI", "QuadSPI-memory";
			clocks = <&syscon_apmu CLK_APMU_QSPI>,
				 <&syscon_apmu CLK_APMU_QSPI_BUS>;
			clock-names = "qspi", "qspi_en";
			resets = <&syscon_apmu RESET_APMU_QSPI>,
				 <&syscon_apmu RESET_APMU_QSPI_BUS>;
			reset-names = "qspi_reset", "qspi_bus_reset";
			interrupts = <117 IRQ_TYPE_LEVEL_HIGH>;
			interrupt-parent = <&saplic>;
			status = "disabled";
		};

		v2d: v2d@c0100000 {
			compatible = "spacemit,v2d";
			reg =  <0x0 0xc0100000 0x0 0x1000>;
			reg-names = "v2dreg";
			clocks = <&syscon_apmu CLK_APMU_LCD_MCLK>,
				 <&syscon_apmu CLK_APMU_V2D>;
			clock-names = "v2d-io", "v2d-core";
			resets = <&syscon_apmu RESET_APMU_V2D>;
			reset-names = "v2d_reset";
			interrupt-parent = <&saplic>;
			interrupts = <86 IRQ_TYPE_LEVEL_HIGH>;
			status = "okay";
		};

		mailbox0: mailbox0@cac90000 {
			compatible = "spacemit,k3-mailbox";
			reg = <0x0 0xcac90000 0x0 0x400>;
			interrupt-parent = <&saplic>;
			interrupts = <210 IRQ_TYPE_LEVEL_HIGH>;
			#mbox-cells = <1>;
			status = "okay";
		};

		mailbox1: mailbox1@cac90400 {
			compatible = "spacemit,k3-mailbox";
			reg = <0x0 0xcac90400 0x0 0x400>;
			interrupt-parent = <&saplic>;
			interrupts = <212 IRQ_TYPE_LEVEL_HIGH>;
			#mbox-cells = <1>;
			status = "okay";
		};

		mailbox2: mailbox2@cac90800 {
			compatible = "spacemit,k3-mailbox";
			reg = <0x0 0xcac90800 0x0 0x400>;
			interrupt-parent = <&saplic>;
			interrupts = <214 IRQ_TYPE_LEVEL_HIGH>;
			#mbox-cells = <1>;
			status = "okay";
		};

		mailbox3: mailbox3@cac90c00 {
			compatible = "spacemit,k3-mailbox";
			reg = <0x0 0xcac90c00 0x0 0x400>;
			interrupt-parent = <&saplic>;
			interrupts = <216 IRQ_TYPE_LEVEL_HIGH>;
			#mbox-cells = <1>;
			status = "okay";
		};

		mailbox4: mailbox4@cac91000 {
			compatible = "spacemit,k3-mailbox";
			reg = <0x0 0xcac91000 0x0 0x400>;
			interrupt-parent = <&saplic>;
			interrupts = <217 IRQ_TYPE_LEVEL_HIGH>;
			#mbox-cells = <1>;
			status = "okay";
		};

		mailbox5: mailbox5@cac91400 {
			compatible = "spacemit,k3-mailbox";
			reg = <0x0 0xcac91400 0x0 0x400>;
			interrupt-parent = <&saplic>;
			interrupts = <226 IRQ_TYPE_LEVEL_HIGH>;
			#mbox-cells = <1>;
			status = "okay";
		};

		mailbox6: mailbox6@cac91800 {
			compatible = "spacemit,k3-mailbox";
			reg = <0x0 0xcac91800 0x0 0x400>;
			interrupt-parent = <&saplic>;
			interrupts = <227 IRQ_TYPE_LEVEL_HIGH>;
			#mbox-cells = <1>;
			status = "okay";
		};

		rcpu0: rcpu_rproc0@0 {
			compatible = "spacemit,k3-rproc";
			reg =  <0 0 0 0>;
			mboxes = <&mailbox3 1>, <&mailbox3 2>;
			mbox-names = "vq0", "vq1";
			firmware-name = "rt24_os0_rcpu.elf";
			memory-region = <&rcpu0_pwr>, <&rcpu0_heap>, <&rcpu0_vdev0vring0>, <&rcpu0_vdev0buffer>,
					<&rcpu0_vdev0vring1>, <&rcpu0_rsc_table>;
			status = "disabled";
		};

		flexcan0: fdcan@d4028000 {
			compatible = "spacemit,k1-flexcan";
			reg = <0x0 0xd4028000 0x0 0x4000>;
			interrupts = <161 IRQ_TYPE_LEVEL_HIGH>;
			interrupt-parent = <&saplic>;
			fsl,clk-source = <0>;
			clocks = <&syscon_apbc CLK_APBC_CAN0>,<&syscon_apbc CLK_APBC_CAN0_BUS>;
			clock-names = "per","ipg";
			resets = <&syscon_apbc RESET_APBC_CAN0>;
			status = "disabled";
		};

		flexcan1: fdcan@d402c000 {
			compatible = "spacemit,k1-flexcan";
			reg = <0x0 0xd402c000 0x0 0x4000>;
			interrupts = <163 IRQ_TYPE_LEVEL_HIGH>;
			interrupt-parent = <&saplic>;
			fsl,clk-source = <0>;
			clocks = <&syscon_apbc CLK_APBC_CAN1>,<&syscon_apbc CLK_APBC_CAN1_BUS>;
			clock-names = "per","ipg";
			resets = <&syscon_apbc RESET_APBC_CAN1>;
			status = "disabled";
		};

		flexcan2: fdcan@d4034000 {
			compatible = "spacemit,k1-flexcan";
			reg = <0x0 0xd4034000 0x0 0x4000>;
			interrupts = <165 IRQ_TYPE_LEVEL_HIGH>;
			interrupt-parent = <&saplic>;
			fsl,clk-source = <0>;
			clocks = <&syscon_apbc CLK_APBC_CAN2>,<&syscon_apbc CLK_APBC_CAN2_BUS>;
			clock-names = "per","ipg";
			resets = <&syscon_apbc RESET_APBC_CAN2>;
			status = "disabled";
		};

		flexcan3: fdcan@d4038000 {
			compatible = "spacemit,k1-flexcan";
			reg = <0x0 0xd4038000 0x0 0x4000>;
			interrupts = <167 IRQ_TYPE_LEVEL_HIGH>;
			interrupt-parent = <&saplic>;
			fsl,clk-source = <0>;
			clocks = <&syscon_apbc CLK_APBC_CAN3>,<&syscon_apbc CLK_APBC_CAN3_BUS>;
			clock-names = "per","ipg";
			resets = <&syscon_apbc RESET_APBC_CAN3>;
			status = "disabled";
		};

		flexcan4: fdcan@d403c000 {
			compatible = "spacemit,k1-flexcan";
			reg = <0x0 0xd403c000 0x0 0x4000>;
			interrupts = <169 IRQ_TYPE_LEVEL_HIGH>;
			interrupt-parent = <&saplic>;
			fsl,clk-source = <0>;
			clocks = <&syscon_apbc CLK_APBC_CAN4>,<&syscon_apbc CLK_APBC_CAN4_BUS>;
			clock-names = "per","ipg";
			resets = <&syscon_apbc RESET_APBC_CAN4>;
			status = "disabled";
		};

		rcpu1: rcpu_rproc1@1 {
			compatible = "spacemit,k3-rproc";
			reg =  <0 0 0 0>;
			mboxes = <&mailbox4 0>, <&mailbox4 1>;
			mbox-names = "vq0", "vq1";
			firmware-name = "rt24_os1_rcpu.elf";
			memory-region = <&rcpu1_runtime>, <&rcpu1_heap>, <&rcpu1_vdev0vring0>, <&rcpu1_vdev0buffer>,
					<&rcpu1_vdev0vring1>, <&rcpu1_rsc_table>;
			status = "okay";
		};

		mpxy_mbox: mpxy_mbox@0 {
			compatible = "riscv,sbi-mpxy-mbox";
			#mbox-cells = <2>;
			status = "okay";
		};

		rpmi_regulator: rpmi_regulator@0 {
			compatible = "riscv,rpmi-regulator";
			mboxes = <&mpxy_mbox 0x0007 0x0>;
			status = "okay";
		};

		rpmi_rtc: rpmi_rtc@0 {
			compatible = "riscv,rpmi-rtc";
			mboxes = <&mpxy_mbox 0xe 0x0>;
			interrupt-parent = <&saplic>;
			interrupts = <64 IRQ_TYPE_LEVEL_HIGH>;
			interrupt-names = "rpmi rtc";
			status = "okay";
		};

		rpmi_pwrkey: rpmi_pwrkey@0 {
			compatible = "riscv,rpmi-pwrkey";
			mboxes = <&mpxy_mbox 0xf 0x0>;
			interrupt-parent = <&saplic>;
			interrupts = <64 IRQ_TYPE_LEVEL_HIGH>;
			interrupt-names = "rpmi pwrkey";
			status = "okay";
		};

		pmu: power-management@0 {
			compatible = "simple-bus";
			#address-cells = <2>;
			#size-cells = <2>;
			ranges;

			power: power-controller {
				compatible = "spacemit,power-controller";
				mboxes = <&mpxy_mbox 0x9 0x0>;
				#power-domain-cells = <1>;
				#address-cells = <1>;
				#size-cells = <0>;
				status = "okay";

				vpu: vpu@0 {
					#power-domain-cells = <0>;
				};

				gpu: gpu@1 {
					#power-domain-cells = <0>;
				};

				audio: audio@2 {
					#power-domain-cells = <0>;
				};

				lcd0: lcd@0 {
					#power-domain-cells = <0>;
				};

				lcd1: lcd@1 {
					#power-domain-cells = <0>;
				};

				dummy: dummy@0 {
					#power-domain-cells = <0>;
				};
			};
		};

		thermal: thermal@d4018000 {
			compatible = "spacemit,k3-tsensor";
			reg = <0x0 0xd4018000 0x0 0x100>;
			interrupt-parent = <&saplic>;
			interrupts = <61 IRQ_TYPE_LEVEL_HIGH>;
			interrupt-names = "tsensor";
			clocks = <&syscon_apbc CLK_APBC_TSEN>,
				<&syscon_apbc CLK_APBC_TSEN_BUS>;
			clock-names = "func", "bus";
			resets = <&syscon_apbc RESET_APBC_TSEN>;
			sensor_range = <0x0 0x7>;
			tsensor_map = <1 0 1 1 1 1 1 1>;
			temperature_offset = <274>;
			#thermal-sensor-cells = <1>;
			status = "okay";
		};

		thermal_zones: thermal-zones {

		};

		timer0: timer@d4016000 {
			compatible = "spacemit,soc-timer";
			reg = <0x0 0xd4016000 0x0 0xc8>;
			spacemit,timer-id = <0>;
			spacemit,timer-fastclk-frequency = <1000000>;
			spacemit,timer-apb-frequency = <102400000>;
			spacemit,timer-frequency = <1000000>;
			clocks = <&syscon_apbc CLK_APBC_TIMERS1>,
				<&syscon_apbc CLK_APBC_TIMERS1_BUS>;
			clock-names = "func", "bus";
			resets = <&syscon_apbc RESET_APBC_TIMERS1>;
			status = "okay";

			counter0 {
				compatible = "spacemit,timer-match";
				interrupts = <26 IRQ_TYPE_LEVEL_HIGH>;
				interrupt-parent = <&saplic>;
				spacemit,timer-broadcast;
				spacemit,timer-counter-id = <0>;
				status = "okay";
			};
		};

		rtc: rtc@d4010000 {
			compatible = "mrvl,mmp-rtc";
			reg = <0x0 0xd4010000 0x0 0x100>;
			interrupt-parent = <&saplic>;
			interrupts = <21 IRQ_TYPE_LEVEL_HIGH>, <22 IRQ_TYPE_LEVEL_HIGH>;
			interrupt-names = "rtc 1Hz", "rtc alarm";
			resets = <&syscon_apbc RESET_APBC_RTC>;
			status = "disabled";
		};

		ircrx0: irc-rx0@d4017e00 {
			compatible = "spacemit-k1,irc";
			reg = <0x0 0xd4017e00 0x0 0x100>;
			interrupts = <69 IRQ_TYPE_LEVEL_HIGH>;
			interrupt-parent = <&saplic>;
			clocks = <&syscon_apbc CLK_APBC_IR0>;
			resets = <&syscon_apbc RESET_APBC_IR0>;
			clock-frequency = <102400000>;
			status = "disabled";
		};

		ircrx1: irc-rx1@d4017f00 {
			compatible = "spacemit-k1,irc";
			reg = <0x0 0xd4017f00 0x0 0x100>;
			interrupts = <20 IRQ_TYPE_LEVEL_HIGH>;
			interrupt-parent = <&saplic>;
			clocks = <&syscon_apbc CLK_APBC_IR1>;
			resets = <&syscon_apbc RESET_APBC_IR1>;
			clock-frequency = <102400000>;
			status = "disabled";
		};

		tcm: tcm@00000000 {
			compatible = "spacemit,k1-tcm";
			reg = <0x0 0 0x0 0x4000000>;
			#address-cells = <1>;
			#size-cells = <1>;
			ranges = <0x0 0x0 0 0x4000000>;
			no-memory-wc;
			/* the first range 0x00000~0x180000 */
			cluster0_tcm@0 {
				reg = <0x00000 0x60000>;
				cpus = <&cpu_8>, <&cpu_9>;
				pool;
			};
			cluster0_tcm@60000 {
				reg = <0x60000 0x60000>;
				cpus = <&cpu_8>, <&cpu_9>;
				pool;
			};
			cluster0_tcm@c0000 {
				reg = <0xc0000 0x60000>;
				cpus = <&cpu_10>, <&cpu_11>;
				pool;
			};
			cluster0_tcm@120000 {
				reg = <0x120000 0x60000>;
				cpus = <&cpu_10>, <&cpu_11>;
				pool;
			};

			/* the second range 0x2000000~0x2180000 */
			cluster1_tcm@2000000 {
				reg = <0x2000000 0x60000>;
				cpus = <&cpu_12>, <&cpu_13>;
				pool;
			};
			cluster1_tcm@2060000 {
				reg = <0x2060000 0x60000>;
				cpus = <&cpu_12>, <&cpu_13>;
				pool;
			};
			cluster1_tcm@20c0000 {
				reg = <0x20c0000 0x60000>;
				cpus = <&cpu_14>, <&cpu_15>;
				pool;
			};
			cluster1_tcm@2120000 {
				reg = <0x2120000 0x60000>;
				cpus = <&cpu_14>, <&cpu_15>;
				pool;
			};
		};

		usb2_host_u2phy: phy@c0a20000 {
			compatible = "spacemit,k3-usb2-phy";
			reg = <0x0 0xc0a20000 0x0 0x200>;
			#phy-cells = <0>;
			status = "disabled";
		};

		usb2_host: usb2@c0a00000 {
			compatible = "spacemit,k1-dwc3";
			reg = <0x0 0xc0a00000 0x0 0x10000>;
			spacemit,syscon-apmu = <&syscon_apmu 0x7c>;
			interrupts = <105 IRQ_TYPE_LEVEL_HIGH>,
				     <155 IRQ_TYPE_LEVEL_HIGH>;
			interrupt-names = "dwc3", "wakeup";
			interrupt-parent = <&saplic>;
			clocks = <&syscon_apmu CLK_APMU_USB2_BUS>;
			resets = <&syscon_apmu RESET_APMU_USB2>;
			phys = <&usb2_host_u2phy>;
			phy-names = "usb2-phy";
			phy_type = "utmi";
			snps,dis_enblslpm_quirk;
			snps,dis_u2_susphy_quirk;
			snps,dis-del-phy-power-chg-quirk;
			snps,dis-tx-ipgap-linecheck-quirk;
			dr_mode = "host";
			maximum-speed = "high-speed";
			status = "disabled";
		};

		usb3_porta_u2phy: phy@cad20000 {
			compatible = "spacemit,k3-usb2-phy";
			reg = <0x0 0xcad20000 0x0 0x200>;
			#phy-cells = <0>;
			status = "disabled";
		};

		usb3_porta_u3phy: phy@cad30000 {
			compatible = "spacemit,k3-usb3-phy",
				     "spacemit,k3-typec-switch";
			spacemit,syscon-apmu = <&syscon_apmu>;
			spacemit,syscon-apb-spare = <&pll>;
			clocks = <&syscon_apmu CLK_APMU_USB3_PORTA_BUS>;
			reg = <0x0 0xcad30000 0x0 0x200>,
			      <0x0 0xcad40000 0x0 0x200>;
			#phy-cells = <0>;
			status = "disabled";
		};

		usb3_porta: usb3@cad00000 {
			compatible = "spacemit,k1-dwc3";
			reg = <0x0 0xcad00000 0x0 0x10000>;
			spacemit,syscon-apmu = <&syscon_apmu 0x3c4>;
			interrupts = <118 IRQ_TYPE_LEVEL_HIGH>,
				     <156 IRQ_TYPE_LEVEL_HIGH>;
			interrupt-names = "dwc3", "wakeup";
			interrupt-parent = <&saplic>;
			clocks = <&syscon_apmu CLK_APMU_USB3_PORTA_BUS>;
			resets = <&syscon_apmu RESET_APMU_USB3_PORTA>;
			phys = <&usb3_porta_u3phy>, <&usb3_porta_u2phy>;
			phy-names = "usb3-phy", "usb2-phy";
			phy_type = "utmi";
			snps,dis_enblslpm_quirk;
			snps,dis_u2_susphy_quirk;
			snps,dis_u3_susphy_quirk;
			snps,dis-del-phy-power-chg-quirk;
			snps,dis-tx-ipgap-linecheck-quirk;
			snps,parkmode-disable-ss-quirk;
			status = "disabled";
		};

		usb3_portb_u2phy: phy@81500000 {
			compatible = "spacemit,k3-usb2-phy";
			reg = <0x0 0x81500000 0x0 0x200>;
			#phy-cells = <0>;
			status = "disabled";
		};

		usb3_portb_u3phy: phy@81f00000{
			compatible = "spacemit,k3-usb3-phy";
			spacemit,syscon-apmu = <&syscon_apmu>;
			spacemit,syscon-apb-spare = <&pll>;
			reg = <0x0 0x81f00000 0x0 0x200>;
			combo-usb-bit = <2>;
			#phy-cells = <0>;
			status = "disabled";
		};

		usb3_portb: usb3@81400000 {
			compatible = "spacemit,k1-dwc3";
			reg = <0x0 0x81400000 0x0 0x10000>;
			spacemit,syscon-apmu = <&syscon_apmu 0x3c8>;
			interrupts = <125 IRQ_TYPE_LEVEL_HIGH>,
				     <157 IRQ_TYPE_LEVEL_HIGH>;
			interrupt-names = "dwc3", "wakeup";
			interrupt-parent = <&saplic>;
			clocks = <&syscon_apmu CLK_APMU_USB3_PORTB_BUS>;
			resets = <&syscon_apmu RESET_APMU_USB3_PORTB>;
			phys = <&usb3_portb_u2phy>, <&usb3_portb_u3phy>;
			phy-names = "usb2-phy", "usb3-phy";
			phy_type = "utmi";
			snps,dis_enblslpm_quirk;
			snps,dis_u2_susphy_quirk;
			snps,dis_u3_susphy_quirk;
			snps,dis-del-phy-power-chg-quirk;
			snps,dis-tx-ipgap-linecheck-quirk;
			snps,parkmode-disable-ss-quirk;
			dr_mode = "host";
			status = "disabled";
		};

		usb3_portc_u2phy: phy@81800000 {
			compatible = "spacemit,k3-usb2-phy";
			reg = <0x0 0x81800000 0x0 0x200>;
			#phy-cells = <0>;
			status = "disabled";
		};

		usb3_portc_u3phy: phy@82000000{
			compatible = "spacemit,k3-usb3-phy";
			spacemit,syscon-apmu = <&syscon_apmu>;
			spacemit,syscon-apb-spare = <&pll>;
			reg = <0x0 0x82000000 0x0 0x200>;
			combo-usb-bit = <1>;
			#phy-cells = <0>;
			status = "disabled";
		};

		usb3_portc: usb3@81700000 {
			compatible = "spacemit,k1-dwc3";
			reg = <0x0 0x81700000 0x0 0x10000>;
			spacemit,syscon-apmu = <&syscon_apmu 0x3cc>;
			interrupts = <148 IRQ_TYPE_LEVEL_HIGH>,
				     <158 IRQ_TYPE_LEVEL_HIGH>;
			interrupt-names = "dwc3", "wakeup";
			interrupt-parent = <&saplic>;
			clocks = <&syscon_apmu CLK_APMU_USB3_PORTC_BUS>;
			resets = <&syscon_apmu RESET_APMU_USB3_PORTC>;
			phys = <&usb3_portc_u2phy>, <&usb3_portc_u3phy>;
			phy-names = "usb2-phy", "usb3-phy";
			phy_type = "utmi";
			snps,dis_enblslpm_quirk;
			snps,dis_u2_susphy_quirk;
			snps,dis_u3_susphy_quirk;
			snps,dis-del-phy-power-chg-quirk;
			snps,dis-tx-ipgap-linecheck-quirk;
			snps,parkmode-disable-ss-quirk;
			dr_mode = "host";
			status = "disabled";
		};

		usb3_portd_u2phy: phy@81b00000 {
			compatible = "spacemit,k3-usb2-phy";
			reg = <0x0 0x81b00000 0x0 0x200>;
			#phy-cells = <0>;
			status = "disabled";
		};

		usb3_portd_u3phy: phy@82100000{
			compatible = "spacemit,k3-usb3-phy";
			spacemit,syscon-apmu = <&syscon_apmu>;
			spacemit,syscon-apb-spare = <&pll>;
			reg = <0x0 0x82100000 0x0 0x200>;
			combo-usb-bit = <0>;
			#phy-cells = <0>;
			status = "disabled";
		};

		usb3_portd: usb3@81a00000 {
			compatible = "spacemit,k1-dwc3";
			reg = <0x0 0x81a00000 0x0 0x10000>;
			spacemit,syscon-apmu = <&syscon_apmu 0x3d0>;
			interrupts = <149 IRQ_TYPE_LEVEL_HIGH>,
				     <159 IRQ_TYPE_LEVEL_HIGH>;
			interrupt-names = "dwc3", "wakeup";
			interrupt-parent = <&saplic>;
			clocks = <&syscon_apmu CLK_APMU_USB3_PORTD_BUS>;
			resets = <&syscon_apmu RESET_APMU_USB3_PORTD>;
			phys = <&usb3_portd_u2phy>, <&usb3_portd_u3phy>;
			phy-names = "usb2-phy", "usb3-phy";
			phy_type = "utmi";
			snps,dis_enblslpm_quirk;
			snps,dis_u2_susphy_quirk;
			snps,dis_u3_susphy_quirk;
			snps,dis-del-phy-power-chg-quirk;
			snps,dis-tx-ipgap-linecheck-quirk;
			snps,parkmode-disable-ss-quirk;
			dr_mode = "host";
			status = "disabled";
		};

		gmac_axi_setup: stmmac-axi-config {
			snps,wr_osr_lmt = <0xf>;
			snps,rd_osr_lmt = <0xf>;
			/* max axi burst len is 256 */
			snps,blen = <256 128 64 32 16 0 0>;
		};

/*
		imggpu: imggpu@cac00000 {
			compatible = "img,rgx";
			interrupt-names = "rgxirq";
			interrupt-parent = <&saplic>;
			interrupts = <75 IRQ_TYPE_LEVEL_HIGH>;
			reg = <0x0 0xcac00000 0x0 0x80000>;
			reg-names = "rgxregs";
			power-domains = <&power K3_PMU_GPU_PWR_DOMAIN>;
			clocks = <&syscon_apmu CLK_APMU_GPU>;
			clock-names = "clk_rgx";
			resets = <&syscon_apmu RESET_APMU_GPU>;
			operating-points-v2 = <&imggpu_opp_table>;
			#cooling-cells = <2>;
			thermal-zone = "thermal_gpu";
			status = "okay";

			imggpu_opp_table: opp-table {
				compatible = "operating-points-v2";

				opp-409000000 {
					opp-hz = /bits/ 64 <409000000>;
					opp-microvolt = <800000>;
					clock-latency-ns = <100000>;
				};

				opp-491000000 {
					opp-hz = /bits/ 64 <491000000>;
					opp-microvolt = <800000>;
					clock-latency-ns = <100000>;
				};

				opp-614000000 {
					opp-hz = /bits/ 64 <614000000>;
					opp-microvolt = <900000>;
					clock-latency-ns = <100000>;
				};

				opp-819000000 {
					opp-hz = /bits/ 64 <819000000>;
					opp-microvolt = <900000>;
					clock-latency-ns = <100000>;
				};

				opp-1000000000 {
					opp-hz = /bits/ 64 <1000000000>;
					opp-microvolt = <950000>;
					clock-latency-ns = <100000>;
				};

				opp-1228000000 {
					opp-hz = /bits/ 64 <1228000000>;
					opp-microvolt = <950000>;
					clock-latency-ns = <100000>;
				};
			};
		};
*/
		imggpu: gpu@cac00000 {
			compatible = "spacemit,k3-gpu", "img,img-bxm-4-64",
				     "img,img-rogue";
			interrupt-parent = <&saplic>;
			interrupts = <75 IRQ_TYPE_LEVEL_HIGH>;
			reg = <0x0 0xcac00000 0x0 0x80000>;
			reg-names = "rgxregs";
			power-domains = <&power K3_PMU_GPU_PWR_DOMAIN>;
			clocks = <&syscon_apmu CLK_APMU_GPU>;
			clock-names = "core";
			resets = <&syscon_apmu RESET_APMU_GPU>;
			#cooling-cells = <2>;
			status = "okay";
		};

                ec_master: ethercat_master {
                        compatible = "spacemit,igh-ec-master";
                        master-count = <1>;
                        status = "disabled";

                        master0 {
                                main-device = <&eth0>;
                        };
		};

		gmac_default_rxq_setup: rx-queues-config {
			snps,rx-queues-to-use = <2>;
			snps,rx-sched-sp;

			queue0 {
				snps,dcb-algorithm;
				snps,priority = <0x0f>;
				snps,map-to-dma-channel = <0>;
			};

			queue1 {
				snps,dcb-algorithm;
				snps,priority = <0xf0>;
				snps,map-to-dma-channel = <1>;
			};
		};

		gmac_default_txq_setup: tx-queues-config {
			snps,tx-queues-to-use = <2>;

			queue0 {
				snps,dcb-algorithm;
			};

			queue1 {
				snps,dcb-algorithm;
			};
		};

		eth0: ethernet@cac80000 {
			compatible = "spacemit,k3-gmac", "snps,dwmac-5.10a";
			reg = <0x0 0xcac80000 0x0 0x2000>;
			spacemit,apmu = <&syscon_apmu>;
			spacemit,ctrl-offset = <0x3e4>;
			spacemit,dline-offset = <0x3e8>;
			clocks = <&syscon_apmu CLK_APMU_EMAC0_BUS>,
				 <&syscon_apmu CLK_APMU_EMAC0_1588>;
			clock-names = "stmmaceth", "ptp_ref";
			resets = <&syscon_apmu RESET_APMU_EMAC0>;
			reset-names = "stmmaceth";
			interrupt-parent = <&saplic>;
			interrupts = <131 IRQ_TYPE_LEVEL_HIGH>, <276 IRQ_TYPE_LEVEL_HIGH>;
			interrupt-names = "macirq", "eth_wake_irq";
			mac-address = [00 00 00 00 00 00];
			tx-fifo-depth = <8192>;
			rx-fifo-depth = <8192>;
			snps,tso;
			snps,force_sf_dma_mode;
			snps,axi-config = <&gmac_axi_setup>;
			snps,mtl-rx-config = <&gmac_default_rxq_setup>;
			snps,mtl-tx-config = <&gmac_default_txq_setup>;
			status = "disabled";
		};

		eth1: ethernet@cac82000 {
			compatible = "spacemit,k3-gmac", "snps,dwmac-5.10a";
			reg = <0x0 0xcac82000 0x0 0x2000>;
			spacemit,apmu = <&syscon_apmu>;
			spacemit,ctrl-offset = <0x3ec>;
			spacemit,dline-offset = <0x3f0>;
			clocks = <&syscon_apmu CLK_APMU_EMAC1_BUS>,
				 <&syscon_apmu CLK_APMU_EMAC1_1588>;
			clock-names = "stmmaceth", "ptp_ref";
			resets = <&syscon_apmu RESET_APMU_EMAC1>;
			reset-names = "stmmaceth";
			interrupt-parent = <&saplic>;
			interrupts = <133 IRQ_TYPE_LEVEL_HIGH>, <277 IRQ_TYPE_LEVEL_HIGH>;
			interrupt-names = "macirq", "eth_wake_irq";
			mac-address = [00 00 00 00 00 00];
			tx-fifo-depth = <8192>;
			rx-fifo-depth = <8192>;
			snps,tso;
			snps,force_sf_dma_mode;
			snps,axi-config = <&gmac_axi_setup>;
			snps,mtl-rx-config = <&gmac_default_rxq_setup>;
			snps,mtl-tx-config = <&gmac_default_txq_setup>;
			status = "disabled";
		};

		eth2: ethernet@cac8e000 {
			compatible = "spacemit,k3-gmac", "snps,dwmac-5.10a";
			reg = <0x0 0xcac8e000 0x0 0x2000>;
			spacemit,apmu = <&syscon_apmu>;
			spacemit,ctrl-offset = <0x248>;
			spacemit,dline-offset = <0x24c>;
			clocks = <&syscon_apmu CLK_APMU_EMAC2_BUS>,
				 <&syscon_apmu CLK_APMU_EMAC2_1588>;
			clock-names = "stmmaceth", "ptp_ref";
			resets = <&syscon_apmu RESET_APMU_EMAC2>;
			reset-names = "stmmaceth";
			interrupt-parent = <&saplic>;
			interrupts = <130 IRQ_TYPE_LEVEL_HIGH>, <278 IRQ_TYPE_LEVEL_HIGH>;
			interrupt-names = "macirq", "eth_wake_irq";
			mac-address = [00 00 00 00 00 00];
			tx-fifo-depth = <8192>;
			rx-fifo-depth = <8192>;
			snps,tso;
			snps,force_sf_dma_mode;
			snps,axi-config = <&gmac_axi_setup>;
			snps,mtl-rx-config = <&gmac_default_rxq_setup>;
			snps,mtl-tx-config = <&gmac_default_txq_setup>;
			status = "disabled";
		};

		eth3: ethernet@a0000000 {
			compatible = "spacemit,k3-gmac", "snps,dwmac-5.10a";
			reg = <0x0 0xa0000000 0x0 0x2000>;
			spacemit,apmu = <&syscon_rcpu_sysctrl>;
			spacemit,ctrl-offset = <0x0e4>;
			spacemit,dline-offset = <0x0e8>;
			clocks = <&syscon_rcpu_sysctrl CLK_RCPU_SYSCTRL_REMAC_BUS>,
				 <&syscon_rcpu_sysctrl CLK_RCPU_SYSCTRL_REMAC_1588>;
			clock-names = "stmmaceth", "ptp_ref";
			resets = <&syscon_rcpu_sysctrl RESET_RCPU_SYSCTRL_RGMAC>;
			reset-names = "stmmaceth";
			interrupt-parent = <&saplic>;
			interrupts = <237 IRQ_TYPE_LEVEL_HIGH>, <236 IRQ_TYPE_LEVEL_HIGH>;
			interrupt-names = "macirq", "eth_wake_irq";
			mac-address = [00 00 00 00 00 00];
			tx-fifo-depth = <4096>;
			rx-fifo-depth = <4096>;
			snps,tso;
			snps,force_sf_dma_mode;
			snps,axi-config = <&gmac_axi_setup>;
			status = "disabled";
		};

		sdcard: mmc@d4280000 {
			compatible = "spacemit,k3-sdhci";
			reg = <0x0 0xd4280000 0x0 0x200>;
			clocks = <&syscon_apmu CLK_APMU_SDH_AXI>,
				 <&syscon_apmu CLK_APMU_SDH0>;
			clock-names = "core", "io";
			interrupt-parent = <&saplic>;
			interrupts = <99 IRQ_TYPE_LEVEL_HIGH>;
			resets = <&syscon_apmu RESET_APMU_SDH_AXI>,
				 <&syscon_apmu RESET_APMU_SDH0>;
			reset-names = "sdh_axi", "sdh0";
			status = "disabled";
		};

		sdio: mmc@d4280800 {
			compatible = "spacemit,k3-sdhci";
			reg = <0x0 0xd4280800 0x0 0x200>;
			clocks = <&syscon_apmu CLK_APMU_SDH_AXI>,
				 <&syscon_apmu CLK_APMU_SDH1>;
			clock-names = "core", "io";
			interrupt-parent = <&saplic>;
			interrupts = <100 IRQ_TYPE_LEVEL_HIGH>;
			resets = <&syscon_apmu RESET_APMU_SDH_AXI>,
				 <&syscon_apmu RESET_APMU_SDH1>;
			reset-names = "sdh_axi", "sdh1";
			status = "disabled";
		};

		emmc: mmc@d4281000 {
			compatible = "spacemit,k3-sdhci";
			reg = <0x0 0xd4281000 0x0 0x200>;
			clocks = <&syscon_apmu CLK_APMU_SDH_AXI>,
				 <&syscon_apmu CLK_APMU_SDH2>;
			clock-names = "core", "io";
			interrupt-parent = <&saplic>;
			interrupts = <101 IRQ_TYPE_LEVEL_HIGH>;
			resets = <&syscon_apmu RESET_APMU_SDH_AXI>,
				 <&syscon_apmu RESET_APMU_SDH2>;
			reset-names = "sdh_axi", "sdh2";
			status = "disabled";
		};

		i2s0: i2s0@d4026000 {
			compatible = "spacemit,k1-i2s";
			#sound-dai-cells = <0>;
			reg = <0x0 0xD4026000 0x0 0x30>;
			clocks = <&syscon_mpmu CLK_MPMU_I2S0_SYSCLK_DIV>,
				 <&syscon_mpmu CLK_MPMU_I2S0_SYSCLK>,
				 <&syscon_apbc CLK_APBC_I2S0_BCLK>,
				 <&syscon_apbc CLK_APBC_I2S0_BUS>,
				 <&syscon_apbc CLK_APBC_I2S0>,
				 <&syscon_mpmu CLK_MPMU_I2S_SYSCLK>,
				 <&syscon_mpmu CLK_MPMU_I2S_BCLK>;
			clock-names = "sysclk_div", "sysclk",
				      "bclk", "sspa_bus", "sspa", "c_sysclk", "c_bclk";
			resets = <&syscon_apbc RESET_APBC_I2S0>;
			assigned-clocks = <&syscon_mpmu CLK_MPMU_I2S_153P6_BASE>,
					  <&syscon_mpmu CLK_MPMU_I2S_SYSCLK_SRC>,
					  <&syscon_mpmu CLK_MPMU_I2S_SYSCLK>,
					  <&syscon_mpmu CLK_MPMU_I2S_BCLK>,
					  <&syscon_mpmu CLK_MPMU_I2S0_SYSCLK_SEL>;
			assigned-clock-rates = <307200000>, <307200000>,
					       <12288000>, <1536000>, <614400000>;
			/* must set to same value when enable multi i2s: 8000/16000/48000Hz */
			/* spacemit,fixed-sample-rate = <48000>; */
			dmas = <&pdma 22>, <&pdma 21>;
			dma-names = "rx", "tx";
			status = "disabled";
		};

		i2s1: i2s1@d4026800 {
			compatible = "spacemit,k1-i2s";
			#sound-dai-cells = <0>;
			reg = <0x0 0xD4026800 0x0 0x30>;
			clocks = <&syscon_mpmu CLK_MPMU_I2S1_SYSCLK>,
				 <&syscon_apbc CLK_APBC_I2S1_BCLK>,
				 <&syscon_apbc CLK_APBC_I2S1_BUS>,
				 <&syscon_apbc CLK_APBC_I2S1>,
				 <&syscon_mpmu CLK_MPMU_I2S_SYSCLK>,
				 <&syscon_mpmu CLK_MPMU_I2S_BCLK>;
			clock-names = "sysclk", "bclk", "sspa_bus", "sspa", "c_sysclk", "c_bclk";
			resets = <&syscon_apbc RESET_APBC_I2S1>;
			assigned-clocks = <&syscon_mpmu CLK_MPMU_I2S_153P6_BASE>,
					  <&syscon_mpmu CLK_MPMU_I2S_SYSCLK_SRC>,
					  <&syscon_mpmu CLK_MPMU_I2S_SYSCLK>,
					  <&syscon_mpmu CLK_MPMU_I2S_BCLK>,
					  <&syscon_mpmu CLK_MPMU_I2S1_SYSCLK_SRC>;
			assigned-clock-rates = <307200000>, <307200000>,
					       <12288000>, <1536000>, <307200000>;
			/* must set to same value when enable multi i2s: 8000/16000/48000Hz */
			/* spacemit,fixed-sample-rate = <48000>; */
			dmas = <&pdma 24>, <&pdma 23>;
			dma-names = "rx", "tx";
			status = "disabled";
		};

		i2s2: i2s2@d4027000 {
			compatible = "spacemit,k1-i2s";
			#sound-dai-cells = <0>;
			reg = <0x0 0xD4027000 0x0 0x30>;
			clocks = <&syscon_mpmu CLK_MPMU_I2S2_SYSCLK_DIV>,
				 <&syscon_mpmu CLK_MPMU_I2S2_SYSCLK>,
				 <&syscon_apbc CLK_APBC_I2S2_BCLK>,
				 <&syscon_apbc CLK_APBC_I2S2_BUS>,
				 <&syscon_apbc CLK_APBC_I2S2>,
				 <&syscon_mpmu CLK_MPMU_I2S_SYSCLK>,
				 <&syscon_mpmu CLK_MPMU_I2S_BCLK>;
			clock-names = "sysclk_div", "sysclk",
				      "bclk", "sspa_bus", "sspa", "c_sysclk", "c_bclk";
			resets = <&syscon_apbc RESET_APBC_I2S2>;
			assigned-clocks = <&syscon_mpmu CLK_MPMU_I2S_153P6_BASE>,
					  <&syscon_mpmu CLK_MPMU_I2S_SYSCLK_SRC>,
					  <&syscon_mpmu CLK_MPMU_I2S_SYSCLK>,
					  <&syscon_mpmu CLK_MPMU_I2S_BCLK>,
					  <&syscon_mpmu CLK_MPMU_I2S2_SYSCLK_SEL>;
			assigned-clock-rates = <307200000>, <307200000>,
					       <12288000>, <1536000>, <614400000>;
			/* must set to same value when enable multi i2s: 8000/16000/48000Hz */
			/* spacemit,fixed-sample-rate = <48000>; */
			dmas = <&pdma 57>, <&pdma 56>;
			dma-names = "rx", "tx";
			status = "disabled";
		};

		i2s3: i2s3@d4027800 {
			compatible = "spacemit,k1-i2s";
			#sound-dai-cells = <0>;
			reg = <0x0 0xD4027800 0x0 0x30>;
			clocks = <&syscon_mpmu CLK_MPMU_I2S3_SYSCLK_DIV>,
				 <&syscon_mpmu CLK_MPMU_I2S3_SYSCLK>,
				 <&syscon_apbc CLK_APBC_I2S3_BCLK>,
				 <&syscon_apbc CLK_APBC_I2S3_BUS>,
				 <&syscon_apbc CLK_APBC_I2S3>,
				 <&syscon_mpmu CLK_MPMU_I2S_SYSCLK>,
				 <&syscon_mpmu CLK_MPMU_I2S_BCLK>;
			clock-names = "sysclk_div", "sysclk",
				      "bclk", "sspa_bus", "sspa", "c_sysclk", "c_bclk";
			resets = <&syscon_apbc RESET_APBC_I2S3>;
			assigned-clocks = <&syscon_mpmu CLK_MPMU_I2S_153P6_BASE>,
					  <&syscon_mpmu CLK_MPMU_I2S_SYSCLK_SRC>,
					  <&syscon_mpmu CLK_MPMU_I2S_SYSCLK>,
					  <&syscon_mpmu CLK_MPMU_I2S_BCLK>,
					  <&syscon_mpmu CLK_MPMU_I2S3_SYSCLK_SEL>;
			assigned-clock-rates = <307200000>, <307200000>,
					       <12288000>, <1536000>, <614400000>;
			/* must set to same value when enable multi i2s: 8000/16000/48000Hz */
			/* spacemit,fixed-sample-rate = <48000>; */
			dmas = <&pdma 59>, <&pdma 58>;
			dma-names = "rx", "tx";
			status = "disabled";
		};

		i2s4: i2s4@d4041000 {
			compatible = "spacemit,k1-i2s";
			#sound-dai-cells = <0>;
			reg = <0x0 0xD4041000 0x0 0x30>;
			clocks = <&syscon_mpmu CLK_MPMU_I2S4_SYSCLK_DIV>,
				 <&syscon_mpmu CLK_MPMU_I2S4_SYSCLK>,
				 <&syscon_apbc CLK_APBC_I2S4_BCLK>,
				 <&syscon_apbc CLK_APBC_I2S4_BUS>,
				 <&syscon_apbc CLK_APBC_I2S4>,
				 <&syscon_mpmu CLK_MPMU_I2S_SYSCLK>,
				 <&syscon_mpmu CLK_MPMU_I2S_BCLK>;
			clock-names = "sysclk_div", "sysclk",
				      "bclk", "sspa_bus", "sspa", "c_sysclk", "c_bclk";
			resets = <&syscon_apbc RESET_APBC_I2S4>;
			assigned-clocks = <&syscon_mpmu CLK_MPMU_I2S_153P6_BASE>,
					  <&syscon_mpmu CLK_MPMU_I2S_SYSCLK_SRC>,
					  <&syscon_mpmu CLK_MPMU_I2S_SYSCLK>,
					  <&syscon_mpmu CLK_MPMU_I2S_BCLK>,
					  <&syscon_mpmu CLK_MPMU_I2S4_SYSCLK_SEL>;
			assigned-clock-rates = <307200000>, <307200000>,
					       <12288000>, <1536000>, <614400000>;
			/* must set to same value when enable multi i2s: 8000/16000/48000Hz */
			/* spacemit,fixed-sample-rate = <48000>; */
			dmas = <&pdma 61>, <&pdma 60>;
			dma-names = "rx", "tx";
			status = "disabled";
		};

		i2s5: i2s5@d4041800 {
			compatible = "spacemit,k1-i2s";
			#sound-dai-cells = <0>;
			reg = <0x0 0xD4041800 0x0 0x30>;
			clocks = <&syscon_mpmu CLK_MPMU_I2S5_SYSCLK_DIV>,
				 <&syscon_mpmu CLK_MPMU_I2S5_SYSCLK>,
				 <&syscon_apbc CLK_APBC_I2S5_BCLK>,
				 <&syscon_apbc CLK_APBC_I2S5_BUS>,
				 <&syscon_apbc CLK_APBC_I2S5>,
				 <&syscon_mpmu CLK_MPMU_I2S_SYSCLK>,
				 <&syscon_mpmu CLK_MPMU_I2S_BCLK>;
			clock-names = "sysclk_div", "sysclk",
				      "bclk", "sspa_bus", "sspa", "c_sysclk", "c_bclk";
			resets = <&syscon_apbc RESET_APBC_I2S5>;
			assigned-clocks = <&syscon_mpmu CLK_MPMU_I2S_153P6_BASE>,
					  <&syscon_mpmu CLK_MPMU_I2S_SYSCLK_SRC>,
					  <&syscon_mpmu CLK_MPMU_I2S_SYSCLK>,
					  <&syscon_mpmu CLK_MPMU_I2S_BCLK>,
					  <&syscon_mpmu CLK_MPMU_I2S5_SYSCLK_SEL>;
			assigned-clock-rates = <307200000>, <307200000>,
					       <12288000>, <1536000>, <614400000>;
			/* must set to same value when enable multi i2s: 8000/16000/48000Hz */
			/* spacemit,fixed-sample-rate = <48000>; */
			dmas = <&pdma 63>, <&pdma 62>;
			dma-names = "rx", "tx";
			status = "disabled";
		};

		sound_card0: sound-card@0 {
			status = "disabled";
			compatible = "simple-audio-card";
		};

		sound_card1: sound-card@1 {
			status = "disabled";
			compatible = "simple-audio-card";
		};

		hwspinlock: hwspin@cac91c00 {
			compatible = "spacemit,hwspinlock";
			reg = <0x0 0xcac91c00 0x0 0x100>;
			status = "disabled";
		};

		ai_dmac0: hdma0@d8804000 {
			compatible = "spacemit-ai-dmac";
			reg = <0x0 0xd8804000 0x0 0x1000>;
			interrupt-parent = <&saplic>;
			interrupts = <7 IRQ_TYPE_LEVEL_HIGH>;
			clocks = <&syscon_dciu CLK_DCIU_HDMA>;
			resets = <&syscon_dciu RESET_DCIU_HDMA>, <&syscon_dciu RESET_DCIU_AXIDMA0>;
			reset-names = "bus", "dma";
			dma-coherent;
			status  = "okay";
		};

		ai_dmac1: hdma1@d8805000 {
			compatible = "spacemit-ai-dmac";
			reg = <0x0 0xd8805000 0x0 0x1000>;
			interrupt-parent = <&saplic>;
			interrupts = <8 IRQ_TYPE_LEVEL_HIGH>;
			clocks = <&syscon_dciu CLK_DCIU_HDMA>;
			resets = <&syscon_dciu RESET_DCIU_HDMA>, <&syscon_dciu RESET_DCIU_AXIDMA1>;
			reset-names = "bus", "dma";
			dma-coherent;
			status = "okay";
		};

		ai_dmac2: hdma2@d8806000 {
			compatible = "spacemit-ai-dmac";
			reg = <0x0 0xd8806000 0x0 0x1000>;
			interrupt-parent = <&saplic>;
			interrupts = <9 IRQ_TYPE_LEVEL_HIGH>;
			clocks = <&syscon_dciu CLK_DCIU_HDMA>;
			resets = <&syscon_dciu RESET_DCIU_HDMA>, <&syscon_dciu RESET_DCIU_AXIDMA2>;
			reset-names = "bus", "dma";
			dma-coherent;
			status = "okay";
		};

		ai_dmac3: hdma3@d8807000 {
			compatible = "spacemit-ai-dmac";
			reg = <0x0 0xd8807000 0x0 0x1000>;
			interrupt-parent = <&saplic>;
			interrupts = <10 IRQ_TYPE_LEVEL_HIGH>;
			clocks = <&syscon_dciu CLK_DCIU_HDMA>;
			resets = <&syscon_dciu RESET_DCIU_HDMA>, <&syscon_dciu RESET_DCIU_AXIDMA3>;
			reset-names = "bus", "dma";
			dma-coherent;
			status = "okay";
		};

		ai_dmac4: hdma4@d8808000 {
			compatible = "spacemit-ai-dmac";
			reg = <0x0 0xd8808000 0x0 0x1000>;
			interrupt-parent = <&saplic>;
			interrupts = <11 IRQ_TYPE_LEVEL_HIGH>;
			clocks = <&syscon_dciu CLK_DCIU_HDMA>;
			resets = <&syscon_dciu RESET_DCIU_HDMA>, <&syscon_dciu RESET_DCIU_AXIDMA4>;
			reset-names = "bus", "dma";
			dma-coherent;
			status  = "okay";
		};

		ai_dmac5: hdma5@d8809000 {
			compatible = "spacemit-ai-dmac";
			reg = <0x0 0xd8809000 0x0 0x1000>;
			interrupt-parent = <&saplic>;
			interrupts = <12 IRQ_TYPE_LEVEL_HIGH>;
			clocks = <&syscon_dciu CLK_DCIU_HDMA>;
			resets = <&syscon_dciu RESET_DCIU_HDMA>, <&syscon_dciu RESET_DCIU_AXIDMA5>;
			reset-names = "bus", "dma";
			dma-coherent;
			status = "okay";
		};

		ai_dmac6: hdma6@d880a000 {
			compatible = "spacemit-ai-dmac";
			reg = <0x0 0xd880a000 0x0 0x1000>;
			interrupt-parent = <&saplic>;
			interrupts = <13 IRQ_TYPE_LEVEL_HIGH>;
			clocks = <&syscon_dciu CLK_DCIU_HDMA>;
			resets = <&syscon_dciu RESET_DCIU_HDMA>, <&syscon_dciu RESET_DCIU_AXIDMA6>;
			reset-names = "bus", "dma";
			dma-coherent;
			status = "okay";
		};

		ai_dmac7: hdma7@d880b000 {
			compatible = "spacemit-ai-dmac";
			reg = <0x0 0xd880b000 0x0 0x1000>;
			interrupt-parent = <&saplic>;
			interrupts = <14 IRQ_TYPE_LEVEL_HIGH>;
			clocks = <&syscon_dciu CLK_DCIU_HDMA>;
			resets = <&syscon_dciu RESET_DCIU_HDMA>, <&syscon_dciu RESET_DCIU_AXIDMA7>;
			reset-names = "bus", "dma";
			dma-coherent;
			status = "okay";
		};

		ai_dmadev: aidma-dev@0 {
			compatible = "ai-dma-dev";
			msi-parent = <&simsic>;
			status = "okay";
		};

		phy0: phy-pcie@81d00000 {
			compatible = "spacemit,k3-pcie-phy";
			reg = <0x0 0x81d00000 0x0 0x1000>;
			spacemit,syscon-apb-spare = <&pll>;
			num-lanes = <2>;
			spacemit,phy-id = <0>;
			#phy-cells = <0>;
			status = "disabled";
		};

		phy1: phy-pcie@81e00000 {
			compatible = "spacemit,k3-pcie-phy";
			reg = <0x0 0x81e00000 0x0 0x1000>;
			spacemit,syscon-apb-spare = <&pll>;
			num-lanes = <2>;
			spacemit,phy-id = <1>;
			#phy-cells = <0>;
			status = "disabled";
		};

		phy2: phy-pcie@81f00000 {
			compatible = "spacemit,k3-pcie-phy";
			reg = <0x0 0x81f00000 0x0 0x1000>;
			spacemit,syscon-apb-spare = <&pll>;
			num-lanes = <1>;
			spacemit,phy-id = <2>;
			#phy-cells = <0>;
			status = "disabled";
		};

		phy3: phy-pcie@82000000 {
			compatible = "spacemit,k3-pcie-phy";
			reg = <0x0 0x82000000 0x0 0x1000>;
			spacemit,syscon-apb-spare = <&pll>;
			num-lanes = <1>;
			spacemit,phy-id = <3>;
			#phy-cells = <0>;
			status = "disabled";
		};

		phy4: phy-pcie@82100000 {
			compatible = "spacemit,k3-pcie-phy";
			reg = <0x0 0x82100000 0x0 0x1000>;
			spacemit,syscon-apb-spare = <&pll>;
			num-lanes = <1>;
			spacemit,phy-id = <4>;
			#phy-cells = <0>;
			status = "disabled";
		};

		phy5: phy-pcie@82200000 {
			compatible = "spacemit,k3-pcie-phy";
			reg = <0x0 0x82200000 0x0 0x1000>;
			spacemit,syscon-apb-spare = <&pll>;
			num-lanes = <1>;
			spacemit,phy-id = <5>;
			#phy-cells = <0>;
			status = "disabled";
		};

		iommu: iommu@c0f00000 {
			compatible = "spacemit,k3-iommu";
			reg = <0x0 0xc0f00000 0x0 0x1000>;
			interrupts = <234 IRQ_TYPE_LEVEL_HIGH>;
			interrupt-parent = <&saplic>;
			#iommu-cells = <0x01>;
			clocks = <&syscon_apmu CLK_APMU_IOMMU>;
			status = "disabled";
		};

		pcie0_rc: pcie@80000000 {
			compatible = "spacemit,k1-pcie";
			reg = <0x0 0x80000000 0x0 0x00001000>, /* dbi */
				<0x0 0x80100000 0x0 0x00001000>, /* dbi2 */
				<0x0 0x80300000 0x0 0x00003f20>, /* atu registers */
				<0x11 0x00000000 0x0 0x00010000>, /* config space */
				<0x0 0x82900000 0x0 0x00001000>; /* phy ahb (link) */
			reg-names = "dbi", "dbi2", "atu", "config", "link";
			bus-range = <0x00 0xff>;
			max-link-speed = <3>;
			num-lanes = <8>;
			device_type = "pci";
			#address-cells = <3>;
			#size-cells = <2>;
			ranges = <0x01000000 0x00 0x00010000 0x11 0x00010000 0x0 0x00100000>,
				<0x02000000 0x0 0x00110000 0x11 0x00110000 0x0 0x7fef0000>,
				<0x43000000 0x18 0x00000000 0x18 0x00000000 0x1 0x00000000>;

			interrupt-parent = <&saplic>;
			interrupts = <141 IRQ_TYPE_LEVEL_HIGH>, <219 IRQ_TYPE_LEVEL_HIGH>;
			interrupt-names = "pcie_irq", "wakeup";
				clocks = <&syscon_apmu CLK_APMU_PCIE_PORTA_BUS>,
					<&syscon_apmu CLK_APMU_PCIE_PORTA_MSTR>,
					<&syscon_apmu CLK_APMU_PCIE_PORTA_SLV>;
				clock-names = "dbi", "mstr", "slv";
				resets = <&syscon_apmu RESET_APMU_PCIE_PORTA_DBI>,
					<&syscon_apmu RESET_APMU_PCIE_PORTA_MSTR>,
					<&syscon_apmu RESET_APMU_PCIE_PORTA_SLV>;
				reset-names = "dbi", "mstr", "slv";
			linux,pci-domain = <0>;
			msi-parent = <&simsic>;
			spacemit,apmu = <&syscon_apmu 0x1f0>;

			iommu-map = <0x0 &iommu 0x00000 0x10000>;

			status = "disabled";
		};

		pcie1_rc: pcie@80400000 {
			compatible = "spacemit,k1-pcie";
			reg = <0x0 0x80400000 0x0 0x00001000>, /* dbi */
				<0x0 0x80500000 0x0 0x00001000>, /* dbi2 */
				<0x0 0x80700000 0x0 0x00003f20>, /* atu registers */
				<0x11 0x80000000 0x0 0x00010000>, /* config space */
				<0x0 0x82c00000 0x0 0x00001000>; /* phy ahb (link) */
			reg-names = "dbi", "dbi2", "atu", "config", "link";

			bus-range = <0x00 0xff>;
			max-link-speed = <3>;
			num-lanes = <2>;
			device_type = "pci";
			#address-cells = <3>;
			#size-cells = <2>;
			ranges = <0x01000000 0x0 0x00010000 0x11 0x80010000 0x0 0x00100000>,
				<0x02000000 0x0 0x80110000 0x11 0x80110000 0x0 0x7fef0000>,
				<0x43000000 0x16 0x00000000 0x16 0x00000000 0x1 0x00000000>;

			interrupt-parent = <&saplic>;
			interrupts = <142 IRQ_TYPE_LEVEL_HIGH>, <220 IRQ_TYPE_LEVEL_HIGH>;
			interrupt-names = "pcie_irq", "wakeup";

			clocks = <&syscon_apmu CLK_APMU_PCIE_PORTB_BUS>,
				<&syscon_apmu CLK_APMU_PCIE_PORTB_MSTR>,
				<&syscon_apmu CLK_APMU_PCIE_PORTB_SLV>;
			clock-names = "dbi", "mstr", "slv";
			resets = <&syscon_apmu RESET_APMU_PCIE_PORTB_DBI>,
				<&syscon_apmu RESET_APMU_PCIE_PORTB_MSTR>,
				<&syscon_apmu RESET_APMU_PCIE_PORTB_SLV>;
			reset-names = "dbi", "mstr", "slv";

			linux,pci-domain = <1>;
			msi-parent = <&simsic>;
			spacemit,pcie-port = <1>;
			spacemit,apmu = <&syscon_apmu 0x1d0>;

			iommu-map = <0x0 &iommu 0x10000 0x10000>;

			status = "disabled";
		};

		pcie2_rc: pcie@80800000 {
			compatible = "spacemit,k1-pcie";
			reg = <0x0 0x80800000 0x0 0x00001000>, /* dbi */
				<0x0 0x80900000 0x0 0x00001000>, /* dbi2 */
				<0x0 0x80b00000 0x0 0x00003f20>, /* atu registers */
				<0x12 0x00000000 0x0 0x00010000>, /* config space */
				<0x0 0x82d00000 0x0 0x00001000>; /* phy ahb (link) */
			reg-names = "dbi", "dbi2", "atu", "config", "link";

			bus-range = <0x00 0xff>;
			max-link-speed = <3>;
			num-lanes = <2>;
			device_type = "pci";
			#address-cells = <3>;
			#size-cells = <2>;
			ranges = <0x01000000 0x00 0x00000000 0x12 0x00010000 0x0 0x00100000>,
				<0x02000000 0x0 0x00110000 0x12 0x00110000 0x0 0x7fef0000>,
				<0x43000000 0x15 0x00000000 0x15 0x00000000 0x1 0x00000000>;

			interrupt-parent = <&saplic>;
			interrupts = <143 IRQ_TYPE_LEVEL_HIGH>, <221 IRQ_TYPE_LEVEL_HIGH>;
			interrupt-names = "pcie_irq", "wakeup";

			clocks = <&syscon_apmu CLK_APMU_PCIE_PORTC_BUS>,
				<&syscon_apmu CLK_APMU_PCIE_PORTC_MSTR>,
				<&syscon_apmu CLK_APMU_PCIE_PORTC_SLV>;
			clock-names = "dbi", "mstr", "slv";
			resets = <&syscon_apmu RESET_APMU_PCIE_PORTC_DBI>,
				<&syscon_apmu RESET_APMU_PCIE_PORTC_MSTR>,
				<&syscon_apmu RESET_APMU_PCIE_PORTC_SLV>;
			reset-names = "dbi", "mstr", "slv";

			linux,pci-domain = <2>;
			msi-parent = <&simsic>;
			spacemit,pcie-port = <2>;
			spacemit,apmu = <&syscon_apmu 0x1c8>;

			iommu-map = <0x0 &iommu 0x20000 0x10000>;

			status = "disabled";
		};

		pcie3_rc: pcie@80c00000 {
			compatible = "spacemit,k1-pcie";
			reg = <0x0 0x80c00000 0x0 0x00001000>, /* dbi */
			      <0x0 0x80d00000 0x0 0x00001000>, /* dbi2 */
			      <0x0 0x80f00000 0x0 0x00003f20>, /* atu registers */
			      <0x12 0x80000000 0x0 0x00010000>, /* config space */
			      <0x0 0x82a00000 0x0 0x00001000>; /* phy ahb (link) */
			reg-names = "dbi", "dbi2", "atu", "config", "link";

			bus-range = <0x00 0xff>;
			max-link-speed = <3>;
			num-lanes = <1>;
			device_type = "pci";
			#address-cells = <3>;
			#size-cells = <2>;
			ranges = <0x01000000 0x0 0x00010000 0x12 0x80010000 0x0 0x100000>,
				<0x02000000 0x0 0x80110000 0x12 0x80110000 0x0 0x3fef0000>,
				<0x43000000 0x14 0x00000000 0x14 0x00000000 0x1 0x00000000>;

			interrupt-parent = <&saplic>;
			interrupts = <145 IRQ_TYPE_LEVEL_HIGH>, <222 IRQ_TYPE_LEVEL_HIGH>;
			interrupt-names = "pcie_irq", "wakeup";

			clocks = <&syscon_apmu CLK_APMU_PCIE_PORTD_BUS>,
				<&syscon_apmu CLK_APMU_PCIE_PORTD_MSTR>,
				<&syscon_apmu CLK_APMU_PCIE_PORTD_SLV>;
			clock-names = "dbi", "mstr", "slv";
			resets = <&syscon_apmu RESET_APMU_PCIE_PORTD_DBI>,
				<&syscon_apmu RESET_APMU_PCIE_PORTD_MSTR>,
				<&syscon_apmu RESET_APMU_PCIE_PORTD_SLV>;
			reset-names = "dbi", "mstr", "slv";

			linux,pci-domain = <3>;
			msi-parent = <&simsic>;
			spacemit,pcie-port = <3>;
			spacemit,apmu = <&syscon_apmu 0x1e0>;
			status = "disabled";
		};

		pcie4_rc: pcie@81000000 {
			compatible = "spacemit,k1-pcie";
			reg = <0x0 0x81000000 0x0 0x00001000>, /* dbi */
			      <0x0 0x81100000 0x0 0x00001000>, /* dbi2 */
			      <0x0 0x81300000 0x0 0x00003f20>, /* atu registers */
			      <0x12 0xc0000000 0x0 0x00010000>, /* config space */
			      <0x0 0x82b00000 0x0 0x00001000>; /* phy ahb (link) */
			reg-names = "dbi", "dbi2", "atu", "config", "link";

			bus-range = <0x00 0xff>;
			max-link-speed = <3>;
			num-lanes = <1>;
			device_type = "pci";
			#address-cells = <3>;
			#size-cells = <2>;
			ranges = <0x01000000 0x0 0x00000000 0x12 0xc0010000 0x0 0x100000>,
				<0x02000000 0x0 0xc0110000 0x12 0xc0110000 0x0 0x3fef0000>,
				<0x43000000 0x13 0x00000000 0x13 0x00000000 0x1 0x00000000>;

			interrupt-parent = <&saplic>;
			interrupts = <146 IRQ_TYPE_LEVEL_HIGH>, <223 IRQ_TYPE_LEVEL_HIGH>;
			interrupt-names = "pcie_irq", "wakeup";

			clocks = <&syscon_apmu CLK_APMU_PCIE_PORTE_BUS>,
				<&syscon_apmu CLK_APMU_PCIE_PORTE_MSTR>,
				<&syscon_apmu CLK_APMU_PCIE_PORTE_SLV>;
			clock-names = "dbi", "mstr", "slv";
			resets = <&syscon_apmu RESET_APMU_PCIE_PORTE_DBI>,
				<&syscon_apmu RESET_APMU_PCIE_PORTE_MSTR>,
				<&syscon_apmu RESET_APMU_PCIE_PORTE_SLV>;
			reset-names = "dbi", "mstr", "slv";

			linux,pci-domain = <4>;
			msi-parent = <&simsic>;
			spacemit,pcie-port = <4>;
			spacemit,apmu = <&syscon_apmu 0x1e8>;
			status = "disabled";
		};

		pcie0_ep: pcie_ep@80000000 {
			compatible = "spacemit,k3-pcie-ep";
			reg = <0x0 0x80000000 0x0 0x00100000>, /* dbi */
				<0x0 0x80100000 0x0 0x00100000>, /* dbi2 */
				<0x0 0x80200000 0x0 0x00001000>, /* elbi */
				<0x0 0x80300000 0x0 0x00001000>, /* atu */
				<0x0 0x80380000 0x0 0x00001000>, /* dma */
				<0x11 0x00000000 0x0 0x10000000>, /* addr_space */
				<0x0 0x82900000 0x0 0x00001000>; /* phy ahb */
			reg-names = "dbi", "dbi2", "elbi", "atu", "dma", "addr_space", "link";

			interrupt-parent = <&saplic>;
			interrupts = <141 IRQ_TYPE_LEVEL_HIGH>, <219 IRQ_TYPE_LEVEL_HIGH>;
			interrupt-names = "dma", "global";

			clocks = <&syscon_apmu CLK_APMU_PCIE_PORTA_BUS>,
				 <&syscon_apmu CLK_APMU_PCIE_PORTA_MSTR>,
				 <&syscon_apmu CLK_APMU_PCIE_PORTA_SLV>;
			clock-names = "dbi", "mstr", "slv";
			resets = <&syscon_apmu RESET_APMU_PCIE_PORTA_DBI>,
				 <&syscon_apmu RESET_APMU_PCIE_PORTA_MSTR>,
				 <&syscon_apmu RESET_APMU_PCIE_PORTA_SLV>;
			reset-names = "dbi", "mstr", "slv";

			spacemit,pcie-port = <0>;
			spacemit,apmu = <&syscon_apmu 0x1f0>;

			msi-parent = <&simsic>;
			max-link-speed = <3>;
			num-lanes = <8>;
			status = "disabled";
		};

		ufshc: ufshc@0xc0e00000 {
			#address-cells = <2>;
			#size-cells = <2>;
			compatible = "spacemit,k3-ufshcd";
			reg = <0x0 0xc0e00000 0x0 0x40000>;
			interrupt-parent = <&saplic>;
			interrupts = <135 0x4>;
			clocks = <&syscon_apmu CLK_APMU_UFS_ACLK>;
			clock-names = "ufs-aclk";
			resets = <&syscon_apmu RESET_APMU_UFS_ACLK>;
			reset-names = "ufs-aclk-rst";
			clock-freq = <491520000>;
			freq-table-hz = <491520000 491520000>;
			lanes-per-direction = <2>;
			ref-clk-freq = <19200000>;
			status = "disabled";
		};

		espi0: espi@cac8c000 {
			compatible = "spacemit,k3-espi";
			reg = <0x0 0xcac8c000 0x0 0x1000>;
			#address-cells = <1>;
			#size-cells = <1>;
			ranges = <0x0 0x0 0x84000000 0x1000>;
			pr-mem-base0 = <0x84000000>;
			pr-mem-base1 = <0xcac8c000>;
			clocks = <&syscon_apmu CLK_APMU_ESPI_SCLK_SRC>,
				 <&syscon_apmu CLK_APMU_ESPI_SCLK>,
				 <&syscon_apmu CLK_APMU_ESPI_MCLK>;
			clock-names = "sclk_src", "sclk", "mclk";
			resets = <&syscon_apmu RESET_APMU_ESPI_MCLK>,
				 <&syscon_apmu RESET_APMU_ESPI_SCLK>;
			assigned-clocks = <&syscon_apmu CLK_APMU_ESPI_SCLK>;
			assigned-clock-parents = <&syscon_apmu CLK_APMU_ESPI_SCLK_SRC>;
			operating-frequency = <20>;
			io-mode = "single";
			alert-mode = "io1";
			alert-type = "open-drain";
			watchdog-timeout = <0xffff>;
			crc-enable;
			auto-gating-enable;
			peripheral-channel-enable;
			vwire-channel-enable;
			oob-channel-enable;
			flash-channel-enable;
			status = "disabled";

			ec: ec@0 {
				compatible = "google,cros-ec-espi";
				reg = <0x0 0x1000>;
				status = "disabled";
			};
		};

		linlon-v5@c0500000 {
			compatible = "arm china,linlon-v5";
			reg = <0x0 0xc0500000 0x0 0x200000>;
			interrupt-parent = <&saplic>;
			interrupts = <74 IRQ_TYPE_LEVEL_HIGH>;
			clocks = <&syscon_apmu CLK_APMU_VPU>;
			clock-names = "vpu_clk";
			power-domains = <&power K3_PMU_VPU_PWR_DOMAIN>;
			resets = <&syscon_apmu RESET_APMU_VPU>;
			status = "okay";
		};

		ccic0: cam_ccic@d420a000 {
			status = "disabled";
		};

		ccic1: cam_ccic@d420a800 {
			status = "disabled";
		};

		ccic2: cam_ccic@d4206000 {
			status = "disabled";
		};

		ccic3: cam_ccic@d4206800 {
			status = "disabled";
		};

		ccic_dma: cam_ccic_dma@d420f000 {
			status = "disabled";
		};

		watchdog: watchdog@d4014000 {
			compatible = "spacemit-k1,wdt";
			clocks = <&syscon_apbc CLK_APBC_TIMERS0>,
				 <&syscon_apbc CLK_APBC_TIMERS0_BUS>;
			clock-names = "clk", "clk-bus";
			resets = <&syscon_apbc RESET_APBC_TIMERS0>;
			reg = <0x0 0xd4014000 0x0 0xff>,
			      <0x0 0xd4050000 0x0 0x1024>;
			interrupts = <35 4>;
			interrupt-parent = <&saplic>;
			spa,wdt-disabled;
			spa,wdt-enable-restart-handler;
			status = "okay";
		};

		ddr_qos: ddrqos@0xd4282c00 {
			compatible = "spacemit,ddr-qos";
			reg = <0x0 0xd4282c00 0x0 0x200>;
			status = "okay";
		};

		reboot_mode_helper: reboot-mode-helper@c087c000 {
			compatible = "spacemit,k3-reboot";
			reg = <0x0 0xc087c000 0x0 0x1000>;
		};

		irq_affinity: irq-aff@0 {
			compatible = "spacemit,irq-affinity-restore";
			msi-parent = <&simsic>;
			status = "okay";
		};
	};
};
